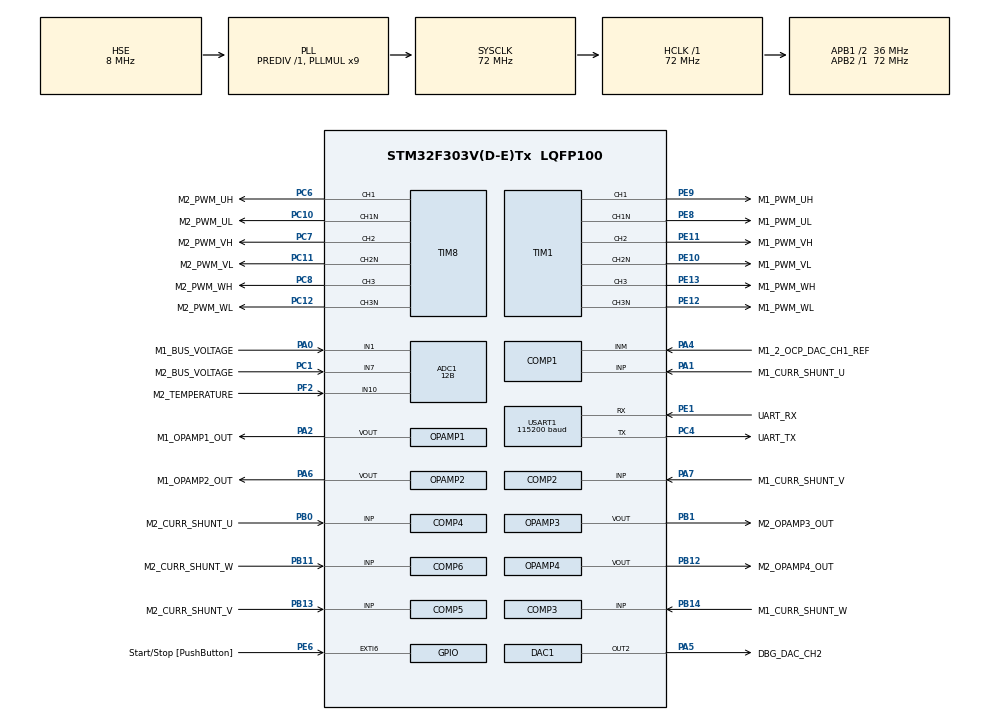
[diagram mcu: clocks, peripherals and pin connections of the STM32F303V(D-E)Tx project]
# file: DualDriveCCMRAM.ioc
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ADC1.Channel-1\#ChannelRegularConversion=ADC_CHANNEL_1
ADC1.Channel-2\#ChannelRegularConversion=ADC_CHANNEL_7
ADC1.Channel-3\#ChannelRegularConversion=ADC_CHANNEL_10
ADC1.ClockPrescaler=ADC_CLOCK_SYNC_PCLK_DIV4
ADC1.ContinuousConvMode=DISABLE
ADC1.DMAContinuousRequests=DISABLE
ADC1.DataAlign=ADC_DATAALIGN_LEFT
ADC1.DiscontinuousConvMode=DISABLE
ADC1.EOCSelection=ADC_EOC_SINGLE_CONV
ADC1.EnableAnalogWatchDog1=false
ADC1.EnableAnalogWatchDog2=false
ADC1.EnableAnalogWatchDog3=false
ADC1.EnableInjectedConversion=ENABLE
ADC1.EnableRegularConversion=ENABLE
ADC1.ExternalTrigConv=ADC_SOFTWARE_START
ADC1.ExternalTrigConvEdge=ADC_EXTERNALTRIGCONVEDGE_NONE
ADC1.ExternalTrigInjecConv=ADC_EXTERNALTRIGINJECCONV_T1_TRGO
ADC1.ExternalTrigInjecConvEdge=ADC_EXTERNALTRIGINJECCONV_EDGE_RISING
ADC1.InjNumberOfConversion=1
ADC1.InjectedChannel-1\#ChannelInjectedConversion=ADC_CHANNEL_3
ADC1.InjectedConvMode=None
ADC1.InjectedOffset-1\#ChannelInjectedConversion=0
ADC1.InjectedOffsetNumber-1\#ChannelInjectedConversion=ADC_OFFSET_NONE
ADC1.InjectedRank-1\#ChannelInjectedConversion=1
ADC1.InjectedSamplingTime-1\#ChannelInjectedConversion=ADC_SAMPLETIME_7CYCLES_5
ADC1.LowPowerAutoWait=DISABLE
ADC1.NbrOfConversion=3
ADC1.NbrOfConversionFlag=1
ADC1.Offset-1\#ChannelRegularConversion=0
ADC1.Offset-2\#ChannelRegularConversion=0
ADC1.Offset-3\#ChannelRegularConversion=0
ADC1.OffsetNumber-1\#ChannelRegularConversion=ADC_OFFSET_NONE
ADC1.OffsetNumber-2\#ChannelRegularConversion=ADC_OFFSET_NONE
ADC1.OffsetNumber-3\#ChannelRegularConversion=ADC_OFFSET_NONE
ADC1.Overrun=ADC_OVR_DATA_PRESERVED
ADC1.QueueInjectedContext=ENABLE
ADC1.Rank-1\#ChannelRegularConversion=1
ADC1.Rank-2\#ChannelRegularConversion=2
ADC1.Rank-3\#ChannelRegularConversion=3
ADC1.Resolution=ADC_RESOLUTION_12B
ADC1.SamplingTime-1\#ChannelRegularConversion=ADC_SAMPLETIME_61CYCLES_5
ADC1.SamplingTime-2\#ChannelRegularConversion=ADC_SAMPLETIME_61CYCLES_5
ADC1.SamplingTime-3\#ChannelRegularConversion=ADC_SAMPLETIME_61CYCLES_5
ADC1.ScanConvMode=ADC_SCAN_ENABLE
ADC1.master=1
ADC2.ClockPrescaler=ADC_CLOCK_SYNC_PCLK_DIV4
ADC2.ContinuousConvMode=DISABLE
ADC2.DMAContinuousRequests=DISABLE
ADC2.DataAlign=ADC_DATAALIGN_LEFT
ADC2.DiscontinuousConvMode=DISABLE
ADC2.EOCSelection=ADC_EOC_SINGLE_CONV
ADC2.EnableAnalogWatchDog1=false
ADC2.EnableAnalogWatchDog2=false
ADC2.EnableAnalogWatchDog3=false
ADC2.EnableInjectedConversion=ENABLE
ADC2.EnableRegularConversion=DISABLE
ADC2.ExternalTrigInjecConv=ADC_EXTERNALTRIGINJECCONV_T1_TRGO
ADC2.ExternalTrigInjecConvEdge=ADC_EXTERNALTRIGINJECCONV_EDGE_RISING
ADC2.InjNumberOfConversion=1
ADC2.InjectedChannel-1\#ChannelInjectedConversion=ADC_CHANNEL_3
ADC2.InjectedConvMode=None
ADC2.InjectedOffset-1\#ChannelInjectedConversion=0
ADC2.InjectedOffsetNumber-1\#ChannelInjectedConversion=ADC_OFFSET_NONE
ADC2.InjectedRank-1\#ChannelInjectedConversion=1
ADC2.InjectedSamplingTime-1\#ChannelInjectedConversion=ADC_SAMPLETIME_7CYCLES_5
ADC2.LowPowerAutoWait=DISABLE
ADC2.Overrun=ADC_OVR_DATA_PRESERVED
ADC2.QueueInjectedContext=ENABLE
ADC2.Resolution=ADC_RESOLUTION_12B
ADC2.ScanConvMode=ADC_SCAN_DISABLE
ADC2.master=1
ADC3.ClockPrescaler=ADC_CLOCK_SYNC_PCLK_DIV4
ADC3.ContinuousConvMode=DISABLE
ADC3.DMAContinuousRequests=DISABLE
ADC3.DataAlign=ADC_DATAALIGN_LEFT
ADC3.DiscontinuousConvMode=DISABLE
ADC3.EOCSelection=ADC_EOC_SINGLE_CONV
ADC3.EnableAnalogWatchDog1=false
ADC3.EnableAnalogWatchDog2=false
ADC3.EnableAnalogWatchDog3=false
ADC3.EnableInjectedConversion=ENABLE
ADC3.EnableRegularConversion=DISABLE
ADC3.ExternalTrigInjecConv=ADC_EXTERNALTRIGINJECCONV_T8_TRGO
ADC3.ExternalTrigInjecConvEdge=ADC_EXTERNALTRIGINJECCONV_EDGE_RISING
ADC3.InjNumberOfConversion=1
ADC3.InjectedChannel-1\#ChannelInjectedConversion=ADC_CHANNEL_1
ADC3.InjectedConvMode=None
ADC3.InjectedOffset-1\#ChannelInjectedConversion=0
ADC3.InjectedOffsetNumber-1\#ChannelInjectedConversion=ADC_OFFSET_NONE
ADC3.InjectedRank-1\#ChannelInjectedConversion=1
ADC3.InjectedSamplingTime-1\#ChannelInjectedConversion=ADC_SAMPLETIME_7CYCLES_5
ADC3.LowPowerAutoWait=DISABLE
ADC3.Overrun=ADC_OVR_DATA_PRESERVED
ADC3.QueueInjectedContext=ENABLE
ADC3.Resolution=ADC_RESOLUTION_12B
ADC3.ScanConvMode=ADC_SCAN_DISABLE
ADC3.master=1
ADC4.ClockPrescaler=ADC_CLOCK_SYNC_PCLK_DIV4
ADC4.ContinuousConvMode=DISABLE
ADC4.DMAContinuousRequests=DISABLE
ADC4.DataAlign=ADC_DATAALIGN_LEFT
ADC4.DiscontinuousConvMode=DISABLE
ADC4.EOCSelection=ADC_EOC_SINGLE_CONV
ADC4.EnableAnalogWatchDog1=false
ADC4.EnableAnalogWatchDog2=false
ADC4.EnableAnalogWatchDog3=false
ADC4.EnableInjectedConversion=ENABLE
ADC4.EnableRegularConversion=DISABLE
ADC4.ExternalTrigInjecConv=ADC_EXTERNALTRIGINJECCONV_T8_TRGO
ADC4.ExternalTrigInjecConvEdge=ADC_EXTERNALTRIGINJECCONV_EDGE_RISING
ADC4.InjNumberOfConversion=1
ADC4.InjectedChannel-1\#ChannelInjectedConversion=ADC_CHANNEL_3
ADC4.InjectedConvMode=None
ADC4.InjectedOffset-1\#ChannelInjectedConversion=0
ADC4.InjectedOffsetNumber-1\#ChannelInjectedConversion=ADC_OFFSET_NONE
ADC4.InjectedRank-1\#ChannelInjectedConversion=1
ADC4.InjectedSamplingTime-1\#ChannelInjectedConversion=ADC_SAMPLETIME_7CYCLES_5
ADC4.LowPowerAutoWait=DISABLE
ADC4.Overrun=ADC_OVR_DATA_PRESERVED
ADC4.QueueInjectedContext=ENABLE
ADC4.Resolution=ADC_RESOLUTION_12B
ADC4.ScanConvMode=ADC_SCAN_DISABLE
ADC4.master=1
COMP1.Output=COMP_OUTPUT_TIM1BKIN2
COMP2.Output=COMP_OUTPUT_TIM1BKIN2
COMP3.Output=COMP_OUTPUT_TIM1BKIN2
COMP4.Output=COMP_OUTPUT_TIM8BKIN2
COMP5.InvertingInput=COMP_INVERTINGINPUT_DAC1_CH1
COMP5.Output=COMP_OUTPUT_TIM8BKIN2
COMP6.InvertingInput=COMP_INVERTINGINPUT_DAC1_CH1
COMP6.Output=COMP_OUTPUT_TIM8BKIN2
DAC1.DAC_OutputBuffer=DAC_OUTPUTBUFFER_DISABLE
DAC1.DAC_OutputBuffer2=DAC_OUTPUTBUFFER_DISABLE
DAC1.DAC_Trigger=DAC_TRIGGER_SOFTWARE
DAC1.DAC_Trigger2=DAC_TRIGGER_SOFTWARE
ExtraMW=MotorControl
ExtraMW.MotorControl.Config=MotorControl
ExtraMW.MotorControl.Mode=MotorControl
ExtraMW.MotorControl.Root=MCSDK_v5.1.2/MotorControl
ExtraMW.MotorControl.Template=templates
Mcu.Family=STM32F3
Mcu.Name=STM32F303V(D-E)Tx
Mcu.Package=LQFP100
MotorControl.ADC_1_PERIPH=ADC1
MotorControl.ADC_1_PERIPH2=ADC3
MotorControl.ADC_2_PERIPH=ADC2
MotorControl.ADC_2_PERIPH2=ADC4
MotorControl.ADC_AHBPERIPH=RCC_AHBPeriph_ADC12
MotorControl.ADC_AHBPERIPH2=RCC_AHBPeriph_ADC34
MotorControl.ADC_CLOCK_WB_DIV=4
MotorControl.ADC_CLOCK_WB_DIV2=4
MotorControl.ADC_CLOCK_WB_FREQ=18
MotorControl.ADC_CLOCK_WB_FREQ2=18
MotorControl.ADC_PERIPH=ADC1
MotorControl.ADC_PERIPH2=ADC3
MotorControl.ALIGNMENT_ANGLE_DEG=90
MotorControl.ALIGNMENT_ANGLE_DEG2=90
MotorControl.ALIGNMENT_DURATION=700
MotorControl.ALIGNMENT_DURATION2=700
MotorControl.AMPLIFICATION_GAIN=1.45
MotorControl.AMPLIFICATION_GAIN2=1.45
MotorControl.ANGC={0,0,0,0,0,0,0,0}
MotorControl.ANGC2={0,0,0,0,0,0,0,0}
MotorControl.BEMF_CONSISTENCY_GAIN=64
MotorControl.BEMF_CONSISTENCY_GAIN2=64
MotorControl.BEMF_CONSISTENCY_TOL=64
MotorControl.BEMF_CONSISTENCY_TOL2=64
MotorControl.BKIN1_FILTER=0
MotorControl.BKIN1_FILTER2=0
MotorControl.BKIN2_FILTER=4
MotorControl.BKIN2_FILTER2=4
MotorControl.BKIN2_MODE=INT_MODE
MotorControl.BKIN2_MODE2=INT_MODE
MotorControl.BKIN_MODE=NONE
MotorControl.BKIN_MODE2=NONE
MotorControl.BOARD=CUSTOM
MotorControl.BRKIN2_GPIO_AF=GPIO_AF_6
MotorControl.BRKIN2_GPIO_AF2=GPIO_AF_10
MotorControl.BRKIN_GPIO_AF=GPIO_AF_2
MotorControl.BRKIN_GPIO_AF2=GPIO_AF_2
MotorControl.BUS_VOLTAGE_READING=true
MotorControl.BUS_VOLTAGE_READING2=true
MotorControl.CCMRAM_ENABLED=true
MotorControl.CLOCK_FREQUENCY=CPU_CLK_72_MHZ
MotorControl.CLOCK_SOURCE=EXTERNAL
MotorControl.CONSTANT1_D=5878
MotorControl.CONSTANT1_D2=5878
MotorControl.CONSTANT1_Q=5878
MotorControl.CONSTANT1_Q2=5878
MotorControl.CONSTANT2_QD=7887
MotorControl.CONSTANT2_QD2=7887
MotorControl.CORD_BEMF_CONSISTENCY_GAIN=64
MotorControl.CORD_BEMF_CONSISTENCY_GAIN2=64
MotorControl.CORD_BEMF_CONSISTENCY_TOL=64
MotorControl.CORD_BEMF_CONSISTENCY_TOL2=64
MotorControl.CORD_F1=2048
MotorControl.CORD_F12=2048
MotorControl.CORD_F2=16384
MotorControl.CORD_F22=16384
MotorControl.CORD_FIFO_DEPTH_01HZ=64
MotorControl.CORD_FIFO_DEPTH_01HZ2=64
MotorControl.CORD_FIFO_DEPTH_DPP=64
MotorControl.CORD_FIFO_DEPTH_DPP2=64
MotorControl.CORD_GAIN1=-3012
MotorControl.CORD_GAIN12=-3012
MotorControl.CORD_GAIN2=15648
MotorControl.CORD_GAIN22=15648
MotorControl.CORD_MAX_ACCEL_DPPP=34
MotorControl.CORD_MAX_ACCEL_DPPP2=34
MotorControl.CORD_MEAS_ERRORS_BEFORE_FAULTS=20
MotorControl.CORD_MEAS_ERRORS_BEFORE_FAULTS2=20
MotorControl.CORD_VARIANCE_THRESHOLD=4
MotorControl.CORD_VARIANCE_THRESHOLD2=4
MotorControl.CPU_CLK_72_MHZ=true
MotorControl.CTRBDID=3
MotorControl.CTRBDID2=3
MotorControl.CURRENT_READING_TOPOLOGY=THREE_SHUNT_INDEPENDENT_RESOURCES
MotorControl.CURRENT_READING_TOPOLOGY2=THREE_SHUNT_INDEPENDENT_RESOURCES2
MotorControl.CURR_SAMPLING_TIME=7
MotorControl.CURR_SAMPLING_TIME2=7
MotorControl.DAC_EMULATED=false
MotorControl.DAC_FUNCTIONALITY=true
MotorControl.DAC_FUNCTIONALITY2=true
MotorControl.DAC_TIMER_CH1_GPIO_PIN=LL_GPIO_PIN_4
MotorControl.DAC_TIMER_CH1_GPIO_PIN2=LL_GPIO_PIN_4
MotorControl.DAC_TIMER_CH1_GPIO_PORT=GPIOA
MotorControl.DAC_TIMER_CH1_GPIO_PORT2=GPIOA
MotorControl.DAC_TIMER_CH2_GPIO_PIN=LL_GPIO_PIN_5
MotorControl.DAC_TIMER_CH2_GPIO_PIN2=LL_GPIO_PIN_5
MotorControl.DAC_TIMER_CH2_GPIO_PORT=GPIOA
MotorControl.DAC_TIMER_CH2_GPIO_PORT2=GPIOA
MotorControl.DAC_TIMER_REMAPPING=NO_REMAP
MotorControl.DAC_TIMER_REMAPPING2=NO_REMAP
MotorControl.DAC_TIMER_SELECTION=TIM3
MotorControl.DAC_TIMER_SELECTION2=TIM3
MotorControl.DC_CURRENT_RS_MEAS=1.60
MotorControl.DC_CURRENT_RS_MEAS2=1.60
MotorControl.DEBUG_DAC_CH1=false
MotorControl.DEBUG_DAC_CH12=false
MotorControl.DEBUG_DAC_CH2=true
MotorControl.DEBUG_DAC_CH22=true
MotorControl.DEFAULT_CONTROL_MODE=STC_SPEED_MODE
MotorControl.DEFAULT_CONTROL_MODE2=STC_SPEED_MODE
MotorControl.DEFAULT_DAC_CHANNEL_1=MC_PROTOCOL_REG_I_A
MotorControl.DEFAULT_DAC_CHANNEL_12=MC_PROTOCOL_REG_I_A
MotorControl.DEFAULT_DAC_CHANNEL_2=MC_PROTOCOL_REG_I_B
MotorControl.DEFAULT_DAC_CHANNEL_22=MC_PROTOCOL_REG_I_B
MotorControl.DEFAULT_DAC_MOTOR=2
MotorControl.DEFAULT_DAC_MOTOR2=2
MotorControl.DEFAULT_FLUX_COMPONENT=0
MotorControl.DEFAULT_FLUX_COMPONENT2=0
MotorControl.DEFAULT_TARGET_SPEED_RPM=1440
MotorControl.DEFAULT_TARGET_SPEED_RPM2=1440
MotorControl.DEFAULT_TORQUE_COMPONENT=0
MotorControl.DEFAULT_TORQUE_COMPONENT2=0
MotorControl.DISSIPATIVE_BRAKE_POLARITY=DOUT_ACTIVE_HIGH
MotorControl.DISSIPATIVE_BRAKE_POLARITY2=DOUT_ACTIVE_HIGH
MotorControl.DRIVES_NUMBER_SELECTION=DUALDRIVE
MotorControl.DUALDRIVE=true
MotorControl.EMERGENCY2_STOP_GPIO_PIN=LL_GPIO_PIN_14
MotorControl.EMERGENCY2_STOP_GPIO_PIN2=LL_GPIO_PIN_6
MotorControl.EMERGENCY2_STOP_GPIO_PORT=GPIOE
MotorControl.EMERGENCY2_STOP_GPIO_PORT2=GPIOB
MotorControl.EMERGENCY_STOP_GPIO_PIN=LL_GPIO_PIN_14
MotorControl.EMERGENCY_STOP_GPIO_PIN2=LL_GPIO_PIN_6
MotorControl.EMERGENCY_STOP_GPIO_PORT=GPIOE
MotorControl.EMERGENCY_STOP_GPIO_PORT2=GPIOB
MotorControl.ENABLE_SL_ALGO_FROM_PHASE=2
MotorControl.ENABLE_SL_ALGO_FROM_PHASE2=2
MotorControl.ENCODER_AVAILABLE=true
MotorControl.ENCODER_AVAILABLE2=true
MotorControl.ENCODER_PPR=400
MotorControl.ENCODER_PPR2=400
MotorControl.ENC_AVERAGING_FIFO_DEPTH=16
MotorControl.ENC_AVERAGING_FIFO_DEPTH2=16
MotorControl.ENC_A_GPIO_PIN=LL_GPIO_PIN_3
MotorControl.ENC_A_GPIO_PIN2=LL_GPIO_PIN_6
MotorControl.ENC_A_GPIO_PORT=GPIOD
MotorControl.ENC_A_GPIO_PORT2=GPIOB
MotorControl.ENC_B_GPIO_PIN=LL_GPIO_PIN_4
MotorControl.ENC_B_GPIO_PIN2=LL_GPIO_PIN_13
MotorControl.ENC_B_GPIO_PORT=GPIOD
MotorControl.ENC_B_GPIO_PORT2=GPIOD
MotorControl.ENC_ICx_FILTER=50
MotorControl.ENC_ICx_FILTER2=50
MotorControl.ENC_INVERT_SPEED=false
MotorControl.ENC_INVERT_SPEED2=false
MotorControl.ENC_MEAS_ERRORS_BEFORE_FAULTS=20
MotorControl.ENC_MEAS_ERRORS_BEFORE_FAULTS2=20
MotorControl.ENC_TIMER_REMAPPING=NO_REMAP_TIM2
MotorControl.ENC_TIMER_REMAPPING2=NO_REMAP_TIM4
MotorControl.ENC_TIMER_SELECTION=ENC_TIM2
MotorControl.ENC_TIMER_SELECTION2=ENC_TIM4
MotorControl.EXT_CLK_8_MHZ=true
MotorControl.EXT_CLOCK_FREQUENCY=EXT_CLK_8_MHZ
MotorControl.F1=2048
MotorControl.F12=2048
MotorControl.F2=16384
MotorControl.F22=16384
MotorControl.FEEDBACK_NET_FILTERING=false
MotorControl.FEEDBACK_NET_FILTERING2=false
MotorControl.FEED_FORWARD_CURRENT_REG_ENABLING=false
MotorControl.FEED_FORWARD_CURRENT_REG_ENABLING2=false
MotorControl.FINAL_I_ALIGNMENT=26390
MotorControl.FINAL_I_ALIGNMENT2=26390
MotorControl.FLUX_WEAKENING_ENABLING=false
MotorControl.FLUX_WEAKENING_ENABLING2=false
MotorControl.FREQ_RATIO2=1
MotorControl.FREQ_RELATION2=HIGHEST_FREQ
MotorControl.FREQ_RELATION22=LOWEST_FREQ
MotorControl.FW_KIDIV=32768
MotorControl.FW_KIDIV2=32768
MotorControl.FW_KI_GAIN=5000
MotorControl.FW_KI_GAIN2=5000
MotorControl.FW_KPDIV=32768
MotorControl.FW_KPDIV2=32768
MotorControl.FW_KP_GAIN=3000
MotorControl.FW_KP_GAIN2=3000
MotorControl.FW_VOLTAGE_REF=985
MotorControl.FW_VOLTAGE_REF2=985
MotorControl.GAIN1=-3012
MotorControl.GAIN12=-3012
MotorControl.GAIN2=15648
MotorControl.GAIN22=15648
MotorControl.H1_GPIO_PIN=LL_GPIO_PIN_3
MotorControl.H1_GPIO_PIN2=LL_GPIO_PIN_6
MotorControl.H1_GPIO_PORT=GPIOD
MotorControl.H1_GPIO_PORT2=GPIOB
MotorControl.H2_GPIO_PIN=LL_GPIO_PIN_4
MotorControl.H2_GPIO_PIN2=LL_GPIO_PIN_13
MotorControl.H2_GPIO_PORT=GPIOD
MotorControl.H2_GPIO_PORT2=GPIOD
MotorControl.H3_GPIO_PIN=LL_GPIO_PIN_7
MotorControl.H3_GPIO_PIN2=LL_GPIO_PIN_8
MotorControl.H3_GPIO_PORT=GPIOD
MotorControl.H3_GPIO_PORT2=GPIOB
MotorControl.HALL_AVERAGING_FIFO_DEPTH=6
MotorControl.HALL_AVERAGING_FIFO_DEPTH2=6
MotorControl.HALL_ICx_FILTER=94
MotorControl.HALL_ICx_FILTER2=94
MotorControl.HALL_MEAS_ERRORS_BEFORE_FAULTS=20
MotorControl.HALL_MEAS_ERRORS_BEFORE_FAULTS2=20
MotorControl.HALL_PHASE_SHIFT=300
MotorControl.HALL_PHASE_SHIFT2=300
MotorControl.HALL_SENSORS_AVAILABLE=true
MotorControl.HALL_SENSORS_AVAILABLE2=true
MotorControl.HALL_SENSORS_PLACEMENT=DEGREES_120
MotorControl.HALL_SENSORS_PLACEMENT2=DEGREES_120
MotorControl.HALL_TIMER_REMAPPING=NO_REMAP_TIM2
MotorControl.HALL_TIMER_REMAPPING2=NO_REMAP_TIM4
MotorControl.HALL_TIMER_SELECTION=HALL_TIM2
MotorControl.HALL_TIMER_SELECTION2=HALL_TIM4
MotorControl.HFI_AMPLITUDE=25
MotorControl.HFI_AMPLITUDE2=25
MotorControl.HFI_DC_0_COEFF=0.00146
MotorControl.HFI_DC_0_COEFF2=0.00146
MotorControl.HFI_DC_1_COEFF=0.002921
MotorControl.HFI_DC_1_COEFF2=0.002921
MotorControl.HFI_DC_2_COEFF=0.00146
MotorControl.HFI_DC_2_COEFF2=0.00146
MotorControl.HFI_DC_3_COEFF=1.889033
MotorControl.HFI_DC_3_COEFF2=1.889033
MotorControl.HFI_DC_4_COEFF=-0.894874
MotorControl.HFI_DC_4_COEFF2=-0.894874
MotorControl.HFI_DEBUG_MODE=false
MotorControl.HFI_DEBUG_MODE2=false
MotorControl.HFI_FREQUENCY=400
MotorControl.HFI_FREQUENCY2=400
MotorControl.HFI_HIFRAMPLSCAN=25
MotorControl.HFI_HIFRAMPLSCAN2=25
MotorControl.HFI_HP_ID_0_COEFF=0.920407
MotorControl.HFI_HP_ID_0_COEFF2=0.920407
MotorControl.HFI_HP_ID_1_COEFF=-1.840814
MotorControl.HFI_HP_ID_1_COEFF2=-1.840814
MotorControl.HFI_HP_ID_2_COEFF=0.920407
MotorControl.HFI_HP_ID_2_COEFF2=0.920407
MotorControl.HFI_HP_ID_3_COEFF=1.834469
MotorControl.HFI_HP_ID_3_COEFF2=1.834469
MotorControl.HFI_HP_ID_4_COEFF=-0.847159
MotorControl.HFI_HP_ID_4_COEFF2=-0.847159
MotorControl.HFI_IDH_DELAY=32400
MotorControl.HFI_IDH_DELAY2=32400
MotorControl.HFI_LOCKFREQ=44
MotorControl.HFI_LOCKFREQ2=44
MotorControl.HFI_LP_ID_0_COEFF=0.010248
MotorControl.HFI_LP_ID_0_COEFF2=0.010248
MotorControl.HFI_LP_ID_1_COEFF=0.020497
MotorControl.HFI_LP_ID_1_COEFF2=0.020497
MotorControl.HFI_LP_ID_2_COEFF=0.010248
MotorControl.HFI_LP_ID_2_COEFF2=0.010248
MotorControl.HFI_LP_ID_3_COEFF=1.693906
MotorControl.HFI_LP_ID_3_COEFF2=1.693906
MotorControl.HFI_LP_ID_4_COEFF=-0.734899
MotorControl.HFI_LP_ID_4_COEFF2=-0.734899
MotorControl.HFI_MAXANGLEDIFF=3640
MotorControl.HFI_MAXANGLEDIFF2=3640
MotorControl.HFI_MINIMUM_SPEED_RPM=402
MotorControl.HFI_MINIMUM_SPEED_RPM2=402
MotorControl.HFI_NOTCH_IQD_0_COEFF=0.959976
MotorControl.HFI_NOTCH_IQD_0_COEFF2=0.959976
MotorControl.HFI_NOTCH_IQD_1_COEFF=-1.893066
MotorControl.HFI_NOTCH_IQD_1_COEFF2=-1.893066
MotorControl.HFI_NOTCH_IQD_2_COEFF=0.959976
MotorControl.HFI_NOTCH_IQD_2_COEFF2=0.959976
MotorControl.HFI_NOTCH_IQD_3_COEFF=1.893066
MotorControl.HFI_NOTCH_IQD_3_COEFF2=1.893066
MotorControl.HFI_NOTCH_IQD_4_COEFF=-0.919953
MotorControl.HFI_NOTCH_IQD_4_COEFF2=-0.919953
MotorControl.HFI_NSDETPOINTSSKIP=10
MotorControl.HFI_NSDETPOINTSSKIP2=10
MotorControl.HFI_NSMAXDETPOINTS=20
MotorControl.HFI_NSMAXDETPOINTS2=20
MotorControl.HFI_NS_MIN_SAT_DIFF=0
MotorControl.HFI_NS_MIN_SAT_DIFF2=0
MotorControl.HFI_PID_KIDIV=32768
MotorControl.HFI_PID_KIDIV2=32768
MotorControl.HFI_PID_KI_DEFAULT=400
MotorControl.HFI_PID_KI_DEFAULT2=400
MotorControl.HFI_PID_KPDIV=16384
MotorControl.HFI_PID_KPDIV2=16384
MotorControl.HFI_PID_KP_DEFAULT=800
MotorControl.HFI_PID_KP_DEFAULT2=800
MotorControl.HFI_PLL_KI_DEFAULT=0.00400
MotorControl.HFI_PLL_KI_DEFAULT2=0.00400
MotorControl.HFI_PLL_KP_DEFAULT=0.00060
MotorControl.HFI_PLL_KP_DEFAULT2=0.00060
MotorControl.HFI_RESTARTTIMESEC=0.1
MotorControl.HFI_RESTARTTIMESEC2=0.1
MotorControl.HFI_RESTART_RPM_TH=(((HFI_STO_RPM_TH)+(STO_HFI_RPM_TH))/2)
MotorControl.HFI_RESTART_RPM_TH2=(((HFI_STO_RPM_TH2)+(STO_HFI_RPM_TH2))/2)
MotorControl.HFI_REVERT_DIRECTION=true
MotorControl.HFI_REVERT_DIRECTION2=true
MotorControl.HFI_SCANROTATIONSNO=3
MotorControl.HFI_SCANROTATIONSNO2=3
MotorControl.HFI_SPD_BUFFER_DEPTH_01HZ=64
MotorControl.HFI_SPD_BUFFER_DEPTH_01HZ2=64
MotorControl.HFI_STEPANGLE=3640
MotorControl.HFI_STEPANGLE2=3640
MotorControl.HFI_STO_RPM_TH=OBS_MINIMUM_SPEED_RPM
MotorControl.HFI_STO_RPM_TH2=OBS_MINIMUM_SPEED_RPM2
MotorControl.HFI_WAITAFTERNS2=4
MotorControl.HFI_WAITAFTERNS22=4
MotorControl.HFI_WAITBEFORESN=6
MotorControl.HFI_WAITBEFORESN2=6
MotorControl.HFI_WAITSYNCH=20
MotorControl.HFI_WAITSYNCH2=20
MotorControl.HFI_WAITTRACK=20
MotorControl.HFI_WAITTRACK2=20
MotorControl.HIGH_SIDE_BRAKE_STATE=false
MotorControl.HIGH_SIDE_BRAKE_STATE2=false
MotorControl.HIGH_SIDE_IDLE_STATE=false
MotorControl.HIGH_SIDE_IDLE_STATE2=false
MotorControl.HW_COMPLEMENTED_LOW_SIDE=false
MotorControl.HW_COMPLEMENTED_LOW_SIDE2=false
MotorControl.HW_DEAD_TIME_NS=100
MotorControl.HW_DEAD_TIME_NS2=100
MotorControl.HW_OV_CURRENT_PROT_BYPASS=false
MotorControl.HW_OV_CURRENT_PROT_BYPASS2=false
MotorControl.ID_DEMAG=-21654
MotorControl.ID_DEMAG2=-21654
MotorControl.INRUSH_CURRLIMIT_AT_POWER_ON=true
MotorControl.INRUSH_CURRLIMIT_AT_POWER_ON2=false
MotorControl.INRUSH_CURRLIMIT_CHANGE_AFTER_MS=1000
MotorControl.INRUSH_CURRLIMIT_CHANGE_AFTER_MS2=1000
MotorControl.INRUSH_CURRLIMIT_ENABLING=false
MotorControl.INRUSH_CURRLIMIT_ENABLING2=false
MotorControl.INRUSH_CURRLIMIT_GPIO_PIN=LL_GPIO_PIN_4
MotorControl.INRUSH_CURRLIMIT_GPIO_PIN2=LL_GPIO_PIN_15
MotorControl.INRUSH_CURRLIMIT_GPIO_PORT=GPIOE
MotorControl.INRUSH_CURRLIMIT_GPIO_PORT2=GPIOD
MotorControl.INRUSH_CURR_LIMITER_POLARITY=DOUT_ACTIVE_HIGH
MotorControl.INRUSH_CURR_LIMITER_POLARITY2=DOUT_ACTIVE_HIGH
MotorControl.INTERNAL_OVERCURRENTPROTECTION=true
MotorControl.INTERNAL_OVERCURRENTPROTECTION2=true
MotorControl.INTERNAL_OVERVOLTAGEPROTECTION=false
MotorControl.INTERNAL_OVERVOLTAGEPROTECTION2=false
MotorControl.IQMAX=21654
MotorControl.IQMAX2=21654
MotorControl.LCD_JOYSTICK_FUNCTIONALITY=false
MotorControl.LCD_JOYSTICK_FUNCTIONALITY2=false
MotorControl.LCD_MODE=LCD_FULL
MotorControl.LCD_MODE2=LCD_FULL
MotorControl.LDLQ_RATIO=1.000
MotorControl.LDLQ_RATIO2=1.000
MotorControl.LOW_SIDE_BRAKE_STATE=false
MotorControl.LOW_SIDE_BRAKE_STATE2=false
MotorControl.LOW_SIDE_IDLE_STATE=false
MotorControl.LOW_SIDE_IDLE_STATE2=false
MotorControl.LOW_SIDE_SIGNALS_ENABLING=LS_PWM_TIMER
MotorControl.LOW_SIDE_SIGNALS_ENABLING2=LS_PWM_TIMER
MotorControl.LS=0.000600
MotorControl.LS2=0.000600
MotorControl.MAX_APPLICATION_SPEED=4000
MotorControl.MAX_APPLICATION_SPEED2=4000
MotorControl.MAX_MODULATION_INDEX=MAX_MODULATION_93_PER_CENT
MotorControl.MAX_MODULATION_INDEX2=MAX_MODULATION_93_PER_CENT2
MotorControl.MCU=STM32F303VE
MotorControl.MCU_SUPPLY_VOLTAGE=3.30
MotorControl.MCU_TYPE=STM32F303xC
MotorControl.MC_WORKBENCH_VERSION=5.1.2.18276
MotorControl.MEAS_ERRORS_BEFORE_FAULTS=20
MotorControl.MEAS_ERRORS_BEFORE_FAULTS2=20
MotorControl.MIN_APPLICATION_SPEED=0
MotorControl.MIN_APPLICATION_SPEED2=0
MotorControl.MOTOR_MAX_SPEED_RPM=4000
MotorControl.MOTOR_MAX_SPEED_RPM2=4000
MotorControl.MOTOR_TYPE=PMSM
MotorControl.MOTOR_TYPE2=PMSM
MotorControl.MOTOR_VOLTAGE_CONSTANT=4.0
MotorControl.MOTOR_VOLTAGE_CONSTANT2=4.0
MotorControl.MTPA_ENABLING=false
MotorControl.MTPA_ENABLING2=false
MotorControl.NB_CONSECUTIVE_TESTS=2
MotorControl.NB_CONSECUTIVE_TESTS2=2
MotorControl.NOMINAL_BUS_VOLTAGE_V=24
MotorControl.NOMINAL_BUS_VOLTAGE_V2=24
MotorControl.NOMINAL_CURRENT=21654
MotorControl.NOMINAL_CURRENT2=21654
MotorControl.OBS_MEAS_ERRORS_BEFORE_FAULTS=20
MotorControl.OBS_MEAS_ERRORS_BEFORE_FAULTS2=20
MotorControl.OBS_MINIMUM_SPEED_RPM=1440
MotorControl.OBS_MINIMUM_SPEED_RPM2=1440
MotorControl.OCPA_INVERTINGINPUT=COMPX_InvertingInput_DAC1
MotorControl.OCPA_INVERTINGINPUT2=COMPX_InvertingInput_DAC1
MotorControl.OCPA_INVERTINGINPUT_GPIO_PIN=LL_GPIO_PIN_4
MotorControl.OCPA_INVERTINGINPUT_GPIO_PIN2=LL_GPIO_PIN_4
MotorControl.OCPA_INVERTINGINPUT_GPIO_PORT=GPIOA
MotorControl.OCPA_INVERTINGINPUT_GPIO_PORT2=GPIOA
MotorControl.OCPA_INVERTINGINPUT_MODE=INT_MODE
MotorControl.OCPA_INVERTINGINPUT_MODE2=INT_MODE
MotorControl.OCPA_NONINVERTINGINPUT=COMP1_NonInvertingInput_PA1
MotorControl.OCPA_NONINVERTINGINPUT2=COMP4_NonInvertingInput_PB0
MotorControl.OCPA_NONINVERTINGINPUT_GPIO_PIN=LL_GPIO_PIN_1
MotorControl.OCPA_NONINVERTINGINPUT_GPIO_PIN2=LL_GPIO_PIN_0
MotorControl.OCPA_NONINVERTINGINPUT_GPIO_PORT=GPIOA
MotorControl.OCPA_NONINVERTINGINPUT_GPIO_PORT2=GPIOB
MotorControl.OCPA_OUTPUT=COMP_Output_TIM1BKIN2
MotorControl.OCPA_OUTPUT2=COMP_Output_TIM8BKIN2
MotorControl.OCPA_OUTPUTPOL=COMP_OutputPol_NonInverted
MotorControl.OCPA_OUTPUTPOL2=COMP_OutputPol_NonInverted
MotorControl.OCPA_OUTPUT_GPIO_AF=GPIO_AF_8
MotorControl.OCPA_OUTPUT_GPIO_AF2=GPIO_AF_8
MotorControl.OCPA_OUTPUT_GPIO_PIN=LL_GPIO_PIN_0
MotorControl.OCPA_OUTPUT_GPIO_PIN2=LL_GPIO_PIN_1
MotorControl.OCPA_OUTPUT_GPIO_PORT=GPIOA
MotorControl.OCPA_OUTPUT_GPIO_PORT2=GPIOB
MotorControl.OCPA_OUTPUT_MODE=INT_MODE
MotorControl.OCPA_OUTPUT_MODE2=INT_MODE
MotorControl.OCPA_SELECTION=COMP1
MotorControl.OCPA_SELECTION2=COMP4
MotorControl.OCPB_INVERTINGINPUT=COMPX_InvertingInput_DAC1
MotorControl.OCPB_INVERTINGINPUT2=COMPX_InvertingInput_DAC1
MotorControl.OCPB_INVERTINGINPUT_GPIO_PIN=LL_GPIO_PIN_4
MotorControl.OCPB_INVERTINGINPUT_GPIO_PIN2=LL_GPIO_PIN_4
MotorControl.OCPB_INVERTINGINPUT_GPIO_PORT=GPIOA
MotorControl.OCPB_INVERTINGINPUT_GPIO_PORT2=GPIOA
MotorControl.OCPB_INVERTINGINPUT_MODE=INT_MODE
MotorControl.OCPB_INVERTINGINPUT_MODE2=INT_MODE
MotorControl.OCPB_NONINVERTINGINPUT=COMP2_NonInvertingInput_PA7
MotorControl.OCPB_NONINVERTINGINPUT2=COMP5_NonInvertingInput_PB13
MotorControl.OCPB_NONINVERTINGINPUT_GPIO_PIN=LL_GPIO_PIN_7
MotorControl.OCPB_NONINVERTINGINPUT_GPIO_PIN2=LL_GPIO_PIN_13
MotorControl.OCPB_NONINVERTINGINPUT_GPIO_PORT=GPIOA
MotorControl.OCPB_NONINVERTINGINPUT_GPIO_PORT2=GPIOB
MotorControl.OCPB_OUTPUT=COMP_Output_TIM1BKIN2
MotorControl.OCPB_OUTPUT2=COMP_Output_TIM8BKIN2
MotorControl.OCPB_OUTPUTPOL=COMP_OutputPol_NonInverted
MotorControl.OCPB_OUTPUTPOL2=COMP_OutputPol_NonInverted
MotorControl.OCPB_OUTPUT_GPIO_AF=GPIO_AF_8
MotorControl.OCPB_OUTPUT_GPIO_AF2=GPIO_AF_7
MotorControl.OCPB_OUTPUT_GPIO_PIN=LL_GPIO_PIN_2
MotorControl.OCPB_OUTPUT_GPIO_PIN2=LL_GPIO_PIN_7
MotorControl.OCPB_OUTPUT_GPIO_PORT=GPIOA
MotorControl.OCPB_OUTPUT_GPIO_PORT2=GPIOC
MotorControl.OCPB_OUTPUT_MODE=INT_MODE
MotorControl.OCPB_OUTPUT_MODE2=INT_MODE
MotorControl.OCPB_SELECTION=COMP2
MotorControl.OCPB_SELECTION2=COMP5
MotorControl.OCPC_INVERTINGINPUT=COMPX_InvertingInput_DAC1
MotorControl.OCPC_INVERTINGINPUT2=COMPX_InvertingInput_DAC1
MotorControl.OCPC_INVERTINGINPUT_GPIO_PIN=LL_GPIO_PIN_4
MotorControl.OCPC_INVERTINGINPUT_GPIO_PIN2=LL_GPIO_PIN_4
MotorControl.OCPC_INVERTINGINPUT_GPIO_PORT=GPIOA
MotorControl.OCPC_INVERTINGINPUT_GPIO_PORT2=GPIOA
MotorControl.OCPC_INVERTINGINPUT_MODE=INT_MODE
MotorControl.OCPC_INVERTINGINPUT_MODE2=INT_MODE
MotorControl.OCPC_NONINVERTINGINPUT=COMP3_NonInvertingInput_PB14
MotorControl.OCPC_NONINVERTINGINPUT2=COMP6_NonInvertingInput_PB11
MotorControl.OCPC_NONINVERTINGINPUT_GPIO_PIN=LL_GPIO_PIN_14
MotorControl.OCPC_NONINVERTINGINPUT_GPIO_PIN2=LL_GPIO_PIN_11
MotorControl.OCPC_NONINVERTINGINPUT_GPIO_PORT=GPIOB
MotorControl.OCPC_NONINVERTINGINPUT_GPIO_PORT2=GPIOB
MotorControl.OCPC_OUTPUT=COMP_Output_TIM1BKIN2
MotorControl.OCPC_OUTPUT2=COMP_Output_TIM8BKIN2
MotorControl.OCPC_OUTPUTPOL=COMP_OutputPol_NonInverted
MotorControl.OCPC_OUTPUTPOL2=COMP_OutputPol_NonInverted
MotorControl.OCPC_OUTPUT_GPIO_AF=GPIO_AF_7
MotorControl.OCPC_OUTPUT_GPIO_AF2=GPIO_AF_8
MotorControl.OCPC_OUTPUT_GPIO_PIN=LL_GPIO_PIN_8
MotorControl.OCPC_OUTPUT_GPIO_PIN2=LL_GPIO_PIN_10
MotorControl.OCPC_OUTPUT_GPIO_PORT=GPIOC
MotorControl.OCPC_OUTPUT_GPIO_PORT2=GPIOA
MotorControl.OCPC_OUTPUT_MODE=INT_MODE
MotorControl.OCPC_OUTPUT_MODE2=INT_MODE
MotorControl.OCPC_SELECTION=COMP3
MotorControl.OCPC_SELECTION2=COMP6
MotorControl.OCPREF=38328
MotorControl.OCPREF2=38328
MotorControl.OCP_COMP_THRESHOLD=0.50
MotorControl.OCP_COMP_THRESHOLD2=0.50
MotorControl.OCP_FILTER=COMP_Mode_HighSpeed
MotorControl.OCP_FILTER2=COMP_Mode_HighSpeed
MotorControl.OCP_INVERTINGINPUT=COMPX_InvertingInput_DAC1
MotorControl.OCP_INVERTINGINPUT2=COMPX_InvertingInput_DAC1
MotorControl.OCP_INVERTINGINPUT_GPIO_PIN=LL_GPIO_PIN_4
MotorControl.OCP_INVERTINGINPUT_GPIO_PIN2=LL_GPIO_PIN_4
MotorControl.OCP_INVERTINGINPUT_GPIO_PORT=GPIOA
MotorControl.OCP_INVERTINGINPUT_GPIO_PORT2=GPIOA
MotorControl.OCP_INVERTINGINPUT_MODE=INT_MODE
MotorControl.OCP_INVERTINGINPUT_MODE2=INT_MODE
MotorControl.OCP_NONINVERTINGINPUT=COMP2_NonInvertingInput_PA7
MotorControl.OCP_NONINVERTINGINPUT2=COMP5_NonInvertingInput_PB13
MotorControl.OCP_NONINVERTINGINPUT_GPIO_PIN=LL_GPIO_PIN_7
MotorControl.OCP_NONINVERTINGINPUT_GPIO_PIN2=LL_GPIO_PIN_13
MotorControl.OCP_NONINVERTINGINPUT_GPIO_PORT=GPIOA
MotorControl.OCP_NONINVERTINGINPUT_GPIO_PORT2=GPIOB
MotorControl.OCP_OUTPUT=COMP_Output_TIM1BKIN2
MotorControl.OCP_OUTPUT2=COMP_Output_TIM8BKIN2
MotorControl.OCP_OUTPUTPOL=COMP_OutputPol_NonInverted
MotorControl.OCP_OUTPUTPOL2=COMP_OutputPol_NonInverted
MotorControl.OCP_OUTPUT_GPIO_AF=GPIO_AF_8
MotorControl.OCP_OUTPUT_GPIO_AF2=GPIO_AF_7
MotorControl.OCP_OUTPUT_GPIO_PIN=LL_GPIO_PIN_2
MotorControl.OCP_OUTPUT_GPIO_PIN2=LL_GPIO_PIN_7
MotorControl.OCP_OUTPUT_GPIO_PORT=GPIOA
MotorControl.OCP_OUTPUT_GPIO_PORT2=GPIOC
MotorControl.OCP_OUTPUT_MODE=INT_MODE
MotorControl.OCP_OUTPUT_MODE2=INT_MODE
MotorControl.OCP_SELECTION=COMP2
MotorControl.OCP_SELECTION2=COMP5
MotorControl.OFST={0,0,0,0,0,0,0,0}
MotorControl.OFST2={0,0,0,0,0,0,0,0}
MotorControl.ON_OVER_VOLTAGE=TURN_OFF_PWM
MotorControl.ON_OVER_VOLTAGE2=TURN_OFF_PWM
MotorControl.OPAMP1_INVERTINGINPUT=OPAMP1_InvertingInput_PGA
MotorControl.OPAMP1_INVERTINGINPUT2=OPAMP3_InvertingInput_PGA
MotorControl.OPAMP1_INVERTINGINPUT_GPIO_PIN=LL_GPIO_PIN_3
MotorControl.OPAMP1_INVERTINGINPUT_GPIO_PIN2=LL_GPIO_PIN_2
MotorControl.OPAMP1_INVERTINGINPUT_GPIO_PORT=GPIOA
MotorControl.OPAMP1_INVERTINGINPUT_GPIO_PORT2=GPIOB
MotorControl.OPAMP1_INVERTINGINPUT_MODE=INT_MODE
MotorControl.OPAMP1_INVERTINGINPUT_MODE2=INT_MODE
MotorControl.OPAMP1_NONINVERTINGINPUT_PHA=OPAMP1_NonInvertingInput_PA1
MotorControl.OPAMP1_NONINVERTINGINPUT_PHA2=OPAMP3_NonInvertingInput_PB0
MotorControl.OPAMP1_NONINVERTINGINPUT_PHA_GPIO_PIN=LL_GPIO_PIN_1
MotorControl.OPAMP1_NONINVERTINGINPUT_PHA_GPIO_PIN2=LL_GPIO_PIN_0
MotorControl.OPAMP1_NONINVERTINGINPUT_PHA_GPIO_PORT=GPIOA
MotorControl.OPAMP1_NONINVERTINGINPUT_PHA_GPIO_PORT2=GPIOB
MotorControl.OPAMP1_NONINVERTINGINPUT_PHB=OPAMP1_NonInvertingInput_PA7
MotorControl.OPAMP1_NONINVERTINGINPUT_PHB2=OPAMP3_NonInvertingInput_PB13
MotorControl.OPAMP1_NONINVERTINGINPUT_PHB_GPIO_PIN=LL_GPIO_PIN_7
MotorControl.OPAMP1_NONINVERTINGINPUT_PHB_GPIO_PIN2=LL_GPIO_PIN_13
MotorControl.OPAMP1_NONINVERTINGINPUT_PHB_GPIO_PORT=GPIOA
MotorControl.OPAMP1_NONINVERTINGINPUT_PHB_GPIO_PORT2=GPIOB
MotorControl.OPAMP1_OUT_GPIO_PIN=LL_GPIO_PIN_2
MotorControl.OPAMP1_OUT_GPIO_PIN2=LL_GPIO_PIN_1
MotorControl.OPAMP1_OUT_GPIO_PORT=GPIOA
MotorControl.OPAMP1_OUT_GPIO_PORT2=GPIOB
MotorControl.OPAMP1_SELECTION=OPAMP1
MotorControl.OPAMP1_SELECTION2=OPAMP3
MotorControl.OPAMP2_INVERTINGINPUT=OPAMP2_InvertingInput_PGA
MotorControl.OPAMP2_INVERTINGINPUT2=OPAMP4_InvertingInput_PGA
MotorControl.OPAMP2_INVERTINGINPUT_GPIO_PIN=LL_GPIO_PIN_5
MotorControl.OPAMP2_INVERTINGINPUT_GPIO_PIN2=LL_GPIO_PIN_10
MotorControl.OPAMP2_INVERTINGINPUT_GPIO_PORT=GPIOC
MotorControl.OPAMP2_INVERTINGINPUT_GPIO_PORT2=GPIOB
MotorControl.OPAMP2_INVERTINGINPUT_MODE=INT_MODE
MotorControl.OPAMP2_INVERTINGINPUT_MODE2=INT_MODE
MotorControl.OPAMP2_NONINVERTINGINPUT_PHA=OPAMP1_NonInvertingInput_PA1
MotorControl.OPAMP2_NONINVERTINGINPUT_PHA2=OPAMP1_NonInvertingInput_PA1
MotorControl.OPAMP2_NONINVERTINGINPUT_PHA_GPIO_PIN=LL_GPIO_PIN_1
MotorControl.OPAMP2_NONINVERTINGINPUT_PHA_GPIO_PIN2=LL_GPIO_PIN_1
MotorControl.OPAMP2_NONINVERTINGINPUT_PHA_GPIO_PORT=GPIOA
MotorControl.OPAMP2_NONINVERTINGINPUT_PHA_GPIO_PORT2=GPIOA
MotorControl.OPAMP2_NONINVERTINGINPUT_PHB=OPAMP2_NonInvertingInput_PA7
MotorControl.OPAMP2_NONINVERTINGINPUT_PHB2=OPAMP4_NonInvertingInput_PB13
MotorControl.OPAMP2_NONINVERTINGINPUT_PHB_GPIO_PIN=LL_GPIO_PIN_7
MotorControl.OPAMP2_NONINVERTINGINPUT_PHB_GPIO_PIN2=LL_GPIO_PIN_13
MotorControl.OPAMP2_NONINVERTINGINPUT_PHB_GPIO_PORT=GPIOA
MotorControl.OPAMP2_NONINVERTINGINPUT_PHB_GPIO_PORT2=GPIOB
MotorControl.OPAMP2_NONINVERTINGINPUT_PHC=OPAMP2_NonInvertingInput_PB14
MotorControl.OPAMP2_NONINVERTINGINPUT_PHC2=OPAMP4_NonInvertingInput_PB11
MotorControl.OPAMP2_NONINVERTINGINPUT_PHC_GPIO_PIN=LL_GPIO_PIN_14
MotorControl.OPAMP2_NONINVERTINGINPUT_PHC_GPIO_PIN2=LL_GPIO_PIN_11
MotorControl.OPAMP2_NONINVERTINGINPUT_PHC_GPIO_PORT=GPIOB
MotorControl.OPAMP2_NONINVERTINGINPUT_PHC_GPIO_PORT2=GPIOB
MotorControl.OPAMP2_OUT_GPIO_PIN=LL_GPIO_PIN_6
MotorControl.OPAMP2_OUT_GPIO_PIN2=LL_GPIO_PIN_12
MotorControl.OPAMP2_OUT_GPIO_PORT=GPIOA
MotorControl.OPAMP2_OUT_GPIO_PORT2=GPIOB
MotorControl.OPAMP2_SELECTION=OPAMP2
MotorControl.OPAMP2_SELECTION2=OPAMP4
MotorControl.OPAMP_INVERTINGINPUT=OPAMP1_InvertingInput_PGA
MotorControl.OPAMP_INVERTINGINPUT2=OPAMP3_InvertingInput_PGA
MotorControl.OPAMP_INVERTINGINPUT_GPIO_PIN=LL_GPIO_PIN_3
MotorControl.OPAMP_INVERTINGINPUT_GPIO_PIN2=LL_GPIO_PIN_2
MotorControl.OPAMP_INVERTINGINPUT_GPIO_PORT=GPIOA
MotorControl.OPAMP_INVERTINGINPUT_GPIO_PORT2=GPIOB
MotorControl.OPAMP_INVERTINGINPUT_MODE=INT_MODE
MotorControl.OPAMP_INVERTINGINPUT_MODE2=INT_MODE
MotorControl.OPAMP_NONINVERTINGINPUT=OPAMP1_NonInvertingInput_PA7
MotorControl.OPAMP_NONINVERTINGINPUT2=OPAMP3_NonInvertingInput_PB13
MotorControl.OPAMP_NONINVERTINGINPUT_GPIO_PIN=LL_GPIO_PIN_7
MotorControl.OPAMP_NONINVERTINGINPUT_GPIO_PIN2=LL_GPIO_PIN_13
MotorControl.OPAMP_NONINVERTINGINPUT_GPIO_PORT=GPIOA
MotorControl.OPAMP_NONINVERTINGINPUT_GPIO_PORT2=GPIOB
MotorControl.OPAMP_OUT_GPIO_PIN=LL_GPIO_PIN_2
MotorControl.OPAMP_OUT_GPIO_PIN2=LL_GPIO_PIN_1
MotorControl.OPAMP_OUT_GPIO_PORT=GPIOA
MotorControl.OPAMP_OUT_GPIO_PORT2=GPIOB
MotorControl.OPAMP_PGACONNECT=OPAMP_PGAConnect_No
MotorControl.OPAMP_PGACONNECT2=OPAMP_PGAConnect_No
MotorControl.OPAMP_PGAGAIN=OPAMP_OPAMP_PGAGain_2
MotorControl.OPAMP_PGAGAIN2=OPAMP_OPAMP_PGAGain_2
MotorControl.OPAMP_SELECTION=OPAMP1
MotorControl.OPAMP_SELECTION2=OPAMP3
MotorControl.OPAMP_TYPE_GAIN=INTERNAL
MotorControl.OPAMP_TYPE_GAIN2=INTERNAL
MotorControl.OPEN_LOOP_FOC=false
MotorControl.OPEN_LOOP_FOC2=false
MotorControl.OPEN_LOOP_K=44
MotorControl.OPEN_LOOP_K2=44
MotorControl.OPEN_LOOP_OFF=4400
MotorControl.OPEN_LOOP_OFF2=4400
MotorControl.OPEN_LOOP_SPEED_RAMP_DURATION_MS=1000
MotorControl.OPEN_LOOP_SPEED_RAMP_DURATION_MS2=1000
MotorControl.OPEN_LOOP_SPEED_RPM=100
MotorControl.OPEN_LOOP_SPEED_RPM2=100
MotorControl.OPEN_LOOP_VF=false
MotorControl.OPEN_LOOP_VF2=false
MotorControl.OPEN_LOOP_VOLTAGE_d=6000
MotorControl.OPEN_LOOP_VOLTAGE_d2=6000
MotorControl.OVERCURR_FEEDBACK_POLARITY=EMSTOP2_ACTIVE_LOW
MotorControl.OVERCURR_FEEDBACK_POLARITY2=EMSTOP2_ACTIVE_LOW
MotorControl.OVERCURR_PROTECTION_HW_DISABLING=DOUT_ACTIVE_HIGH
MotorControl.OVERCURR_PROTECTION_HW_DISABLING2=DOUT_ACTIVE_HIGH
MotorControl.OVPREF=23830
MotorControl.OVPREF2=23830
MotorControl.OVP_FILTER=COMP_Mode_HighSpeed
MotorControl.OVP_FILTER2=COMP_Mode_HighSpeed
MotorControl.OVP_INVERTINGINPUT=COMPX_InvertingInput_VREF
MotorControl.OVP_INVERTINGINPUT2=COMPX_InvertingInput_VREF
MotorControl.OVP_INVERTINGINPUT_GPIO_PIN=LL_GPIO_PIN_4
MotorControl.OVP_INVERTINGINPUT_GPIO_PIN2=LL_GPIO_PIN_4
MotorControl.OVP_INVERTINGINPUT_GPIO_PORT=GPIOA
MotorControl.OVP_INVERTINGINPUT_GPIO_PORT2=GPIOA
MotorControl.OVP_INVERTINGINPUT_MODE=INT_MODE
MotorControl.OVP_INVERTINGINPUT_MODE2=INT_MODE
MotorControl.OVP_NONINVERTINGINPUT=COMP1_NonInvertingInput_PA1
MotorControl.OVP_NONINVERTINGINPUT2=COMP1_NonInvertingInput_PA1
MotorControl.OVP_NONINVERTINGINPUT_GPIO_PIN=LL_GPIO_PIN_1
MotorControl.OVP_NONINVERTINGINPUT_GPIO_PIN2=LL_GPIO_PIN_1
MotorControl.OVP_NONINVERTINGINPUT_GPIO_PORT=GPIOA
MotorControl.OVP_NONINVERTINGINPUT_GPIO_PORT2=GPIOA
MotorControl.OVP_OUTPUT=COMP_Output_TIM1BKIN
MotorControl.OVP_OUTPUT2=COMP_Output_TIM8BKIN
MotorControl.OVP_OUTPUTPOL=COMP_OutputPol_NonInverted
MotorControl.OVP_OUTPUTPOL2=COMP_OutputPol_NonInverted
MotorControl.OVP_OUTPUT_GPIO_AF=GPIO_AF_8
MotorControl.OVP_OUTPUT_GPIO_AF2=GPIO_AF_8
MotorControl.OVP_OUTPUT_GPIO_PIN=LL_GPIO_PIN_0
MotorControl.OVP_OUTPUT_GPIO_PIN2=LL_GPIO_PIN_0
MotorControl.OVP_OUTPUT_GPIO_PORT=GPIOA
MotorControl.OVP_OUTPUT_GPIO_PORT2=GPIOA
MotorControl.OVP_OUTPUT_MODE=EXT_MODE
MotorControl.OVP_OUTPUT_MODE2=EXT_MODE
MotorControl.OVP_SELECTION=COMP1
MotorControl.OVP_SELECTION2=COMP1
MotorControl.OV_CURR_BYPASS_GPIO_PIN=LL_GPIO_PIN_5
MotorControl.OV_CURR_BYPASS_GPIO_PIN2=LL_GPIO_PIN_10
MotorControl.OV_CURR_BYPASS_GPIO_PORT=GPIOE
MotorControl.OV_CURR_BYPASS_GPIO_PORT2=GPIOF
MotorControl.OV_TEMPERATURE_HYSTERESIS_C=10
MotorControl.OV_TEMPERATURE_HYSTERESIS_C2=10
MotorControl.OV_TEMPERATURE_PROT_ENABLING=false
MotorControl.OV_TEMPERATURE_PROT_ENABLING2=true
MotorControl.OV_TEMPERATURE_THRESHOLD_C=70
MotorControl.OV_TEMPERATURE_THRESHOLD_C2=70
MotorControl.OV_VOLTAGE_PROT_ENABLING=true
MotorControl.OV_VOLTAGE_PROT_ENABLING2=true
MotorControl.OV_VOLTAGE_THRESHOLD_V=32
MotorControl.OV_VOLTAGE_THRESHOLD_V2=32
MotorControl.PHASE1_DURATION=1000
MotorControl.PHASE1_DURATION2=1000
MotorControl.PHASE1_FINAL_CURRENT=20300
MotorControl.PHASE1_FINAL_CURRENT2=20300
MotorControl.PHASE1_FINAL_SPEED_RPM=0
MotorControl.PHASE1_FINAL_SPEED_RPM2=0
MotorControl.PHASE2_DURATION=1600
MotorControl.PHASE2_DURATION2=1600
MotorControl.PHASE2_FINAL_CURRENT=20300
MotorControl.PHASE2_FINAL_CURRENT2=20300
MotorControl.PHASE2_FINAL_SPEED_RPM=1600
MotorControl.PHASE2_FINAL_SPEED_RPM2=1600
MotorControl.PHASE3_DURATION=0
MotorControl.PHASE3_DURATION2=0
MotorControl.PHASE3_FINAL_CURRENT=20300
MotorControl.PHASE3_FINAL_CURRENT2=20300
MotorControl.PHASE3_FINAL_SPEED_RPM=1600
MotorControl.PHASE3_FINAL_SPEED_RPM2=1600
MotorControl.PHASE4_DURATION=0
MotorControl.PHASE4_DURATION2=0
MotorControl.PHASE4_FINAL_CURRENT=20300
MotorControl.PHASE4_FINAL_CURRENT2=20300
MotorControl.PHASE4_FINAL_SPEED_RPM=1600
MotorControl.PHASE4_FINAL_SPEED_RPM2=1600
MotorControl.PHASE5_DURATION=0
MotorControl.PHASE5_DURATION2=0
MotorControl.PHASE5_FINAL_CURRENT=20300
MotorControl.PHASE5_FINAL_CURRENT2=20300
MotorControl.PHASE5_FINAL_SPEED_RPM=1600
MotorControl.PHASE5_FINAL_SPEED_RPM2=1600
MotorControl.PHASE_CURRENTS_ADC=ADC1_2
MotorControl.PHASE_CURRENTS_ADC2=ADC3
MotorControl.PHASE_CURRENTS_CHANNEL=ADC_CHANNEL_9
MotorControl.PHASE_CURRENTS_CHANNEL2=ADC_CHANNEL_1
MotorControl.PHASE_CURRENTS_GPIO_PIN=LL_GPIO_PIN_3
MotorControl.PHASE_CURRENTS_GPIO_PIN2=LL_GPIO_PIN_1
MotorControl.PHASE_CURRENTS_GPIO_PORT=GPIOC
MotorControl.PHASE_CURRENTS_GPIO_PORT2=GPIOB
MotorControl.PHASE_UH_GPIO_AF=GPIO_AF_2
MotorControl.PHASE_UH_GPIO_AF2=GPIO_AF_4
MotorControl.PHASE_UH_GPIO_PIN=LL_GPIO_PIN_9
MotorControl.PHASE_UH_GPIO_PIN2=LL_GPIO_PIN_6
MotorControl.PHASE_UH_GPIO_PORT=GPIOE
MotorControl.PHASE_UH_GPIO_PORT2=GPIOC
MotorControl.PHASE_UH_POLARITY=H_ACTIVE_HIGH
MotorControl.PHASE_UH_POLARITY2=H_ACTIVE_HIGH
MotorControl.PHASE_UL_GPIO_AF=GPIO_AF_2
MotorControl.PHASE_UL_GPIO_AF2=GPIO_AF_4
MotorControl.PHASE_UL_GPIO_PIN=LL_GPIO_PIN_8
MotorControl.PHASE_UL_GPIO_PIN2=LL_GPIO_PIN_10
MotorControl.PHASE_UL_GPIO_PORT=GPIOE
MotorControl.PHASE_UL_GPIO_PORT2=GPIOC
MotorControl.PHASE_UL_POLARITY=L_ACTIVE_HIGH
MotorControl.PHASE_UL_POLARITY2=L_ACTIVE_HIGH
MotorControl.PHASE_U_CURR_ADC=ADC1
MotorControl.PHASE_U_CURR_ADC2=ADC3
MotorControl.PHASE_U_CURR_CHANNEL=ADC_CHANNEL_3
MotorControl.PHASE_U_CURR_CHANNEL2=ADC_CHANNEL_1
MotorControl.PHASE_U_GPIO_PIN=LL_GPIO_PIN_2
MotorControl.PHASE_U_GPIO_PIN2=LL_GPIO_PIN_1
MotorControl.PHASE_U_GPIO_PORT=GPIOA
MotorControl.PHASE_U_GPIO_PORT2=GPIOB
MotorControl.PHASE_VH_GPIO_AF=GPIO_AF_2
MotorControl.PHASE_VH_GPIO_AF2=GPIO_AF_4
MotorControl.PHASE_VH_GPIO_PIN=LL_GPIO_PIN_11
MotorControl.PHASE_VH_GPIO_PIN2=LL_GPIO_PIN_7
MotorControl.PHASE_VH_GPIO_PORT=GPIOE
MotorControl.PHASE_VH_GPIO_PORT2=GPIOC
MotorControl.PHASE_VH_POLARITY=H_ACTIVE_HIGH
MotorControl.PHASE_VH_POLARITY2=H_ACTIVE_HIGH
MotorControl.PHASE_VL_GPIO_AF=GPIO_AF_2
MotorControl.PHASE_VL_GPIO_AF2=GPIO_AF_4
MotorControl.PHASE_VL_GPIO_PIN=LL_GPIO_PIN_10
MotorControl.PHASE_VL_GPIO_PIN2=LL_GPIO_PIN_11
MotorControl.PHASE_VL_GPIO_PORT=GPIOE
MotorControl.PHASE_VL_GPIO_PORT2=GPIOC
MotorControl.PHASE_VL_POLARITY=L_ACTIVE_HIGH
MotorControl.PHASE_VL_POLARITY2=L_ACTIVE_HIGH
MotorControl.PHASE_V_CURR_ADC=ADC2
MotorControl.PHASE_V_CURR_ADC2=ADC4
MotorControl.PHASE_V_CURR_CHANNEL=ADC_CHANNEL_3
MotorControl.PHASE_V_CURR_CHANNEL2=ADC_CHANNEL_3
MotorControl.PHASE_V_GPIO_PIN=LL_GPIO_PIN_6
MotorControl.PHASE_V_GPIO_PIN2=LL_GPIO_PIN_12
MotorControl.PHASE_V_GPIO_PORT=GPIOA
MotorControl.PHASE_V_GPIO_PORT2=GPIOB
MotorControl.PHASE_WH_GPIO_AF=GPIO_AF_2
MotorControl.PHASE_WH_GPIO_AF2=GPIO_AF_4
MotorControl.PHASE_WH_GPIO_PIN=LL_GPIO_PIN_13
MotorControl.PHASE_WH_GPIO_PIN2=LL_GPIO_PIN_8
MotorControl.PHASE_WH_GPIO_PORT=GPIOE
MotorControl.PHASE_WH_GPIO_PORT2=GPIOC
MotorControl.PHASE_WH_POLARITY=H_ACTIVE_HIGH
MotorControl.PHASE_WH_POLARITY2=H_ACTIVE_HIGH
MotorControl.PHASE_WL_GPIO_AF=GPIO_AF_2
MotorControl.PHASE_WL_GPIO_AF2=GPIO_AF_4
MotorControl.PHASE_WL_GPIO_PIN=LL_GPIO_PIN_12
MotorControl.PHASE_WL_GPIO_PIN2=LL_GPIO_PIN_12
MotorControl.PHASE_WL_GPIO_PORT=GPIOE
MotorControl.PHASE_WL_GPIO_PORT2=GPIOC
MotorControl.PHASE_WL_POLARITY=L_ACTIVE_HIGH
MotorControl.PHASE_WL_POLARITY2=L_ACTIVE_HIGH
MotorControl.PHASE_W_CURR_ADC=ADC1_2
MotorControl.PHASE_W_CURR_ADC2=ADC3_4
MotorControl.PHASE_W_CURR_CHANNEL=ADC_CHANNEL_6
MotorControl.PHASE_W_CURR_CHANNEL2=ADC_CHANNEL_7
MotorControl.PHASE_W_GPIO_PIN=LL_GPIO_PIN_0
MotorControl.PHASE_W_GPIO_PIN2=LL_GPIO_PIN_10
MotorControl.PHASE_W_GPIO_PORT=GPIOC
MotorControl.PHASE_W_GPIO_PORT2=GPIOD
MotorControl.PID_FLUX_KD_DEFAULT=100
MotorControl.PID_FLUX_KD_DEFAULT2=100
MotorControl.PID_FLUX_KI_DEFAULT=463
MotorControl.PID_FLUX_KI_DEFAULT2=463
MotorControl.PID_FLUX_KP_DEFAULT=2975
MotorControl.PID_FLUX_KP_DEFAULT2=2975
MotorControl.PID_SPEED_KD_DEFAULT=0
MotorControl.PID_SPEED_KD_DEFAULT2=0
MotorControl.PID_SPEED_KI_DEFAULT=3502
MotorControl.PID_SPEED_KI_DEFAULT2=3502
MotorControl.PID_SPEED_KP_DEFAULT=2443
MotorControl.PID_SPEED_KP_DEFAULT2=2443
MotorControl.PID_TORQUE_KD_DEFAULT=100
MotorControl.PID_TORQUE_KD_DEFAULT2=100
MotorControl.PID_TORQUE_KI_DEFAULT=463
MotorControl.PID_TORQUE_KI_DEFAULT2=463
MotorControl.PID_TORQUE_KP_DEFAULT=2975
MotorControl.PID_TORQUE_KP_DEFAULT2=2975
MotorControl.PLL_KI_GAIN=13
MotorControl.PLL_KI_GAIN2=13
MotorControl.PLL_KP_GAIN=284
MotorControl.PLL_KP_GAIN2=284
MotorControl.POLE_PAIR_NUM=2
MotorControl.POLE_PAIR_NUM2=2
MotorControl.PWBDID=22
MotorControl.PWBDID2=22
MotorControl.PWM_FREQUENCY=15000
MotorControl.PWM_FREQUENCY2=15000
MotorControl.PWM_TIMER_REMAPPING=PWM_NO_REMAP
MotorControl.PWM_TIMER_REMAPPING2=PWM_NO_REMAP
MotorControl.PWM_TIMER_SELECTION=PWM_TIM1
MotorControl.PWM_TIMER_SELECTION2=PWM_TIM8
MotorControl.REGCONVADC=ADC1
MotorControl.REGCONVADC2=ADC1
MotorControl.REGULATION_EXECUTION_RATE=1
MotorControl.REGULATION_EXECUTION_RATE2=1
MotorControl.RS=0.35
MotorControl.RS2=0.35
MotorControl.RSHUNT=0.470
MotorControl.RSHUNT2=0.470
MotorControl.R_BRAKE_GPIO_PIN=LL_GPIO_PIN_5
MotorControl.R_BRAKE_GPIO_PIN2=LL_GPIO_PIN_10
MotorControl.R_BRAKE_GPIO_PORT=GPIOE
MotorControl.R_BRAKE_GPIO_PORT2=GPIOF
MotorControl.R_BRAKE_SWITCH_OFF_THRES_V=26
MotorControl.R_BRAKE_SWITCH_OFF_THRES_V2=26
MotorControl.SEGDIV=0
MotorControl.SEGDIV2=0
MotorControl.SERIAL_COMMUNICATION=true
MotorControl.SERIAL_COMMUNICATION2=true
MotorControl.SERIAL_COM_CHANNEL1=MC_PROTOCOL_REG_I_A
MotorControl.SERIAL_COM_CHANNEL12=MC_PROTOCOL_REG_I_A
MotorControl.SERIAL_COM_CHANNEL2=MC_PROTOCOL_REG_I_A
MotorControl.SERIAL_COM_CHANNEL22=MC_PROTOCOL_REG_I_A
MotorControl.SERIAL_COM_MODE=COM_BIDIRECTIONAL
MotorControl.SERIAL_COM_MODE2=COM_BIDIRECTIONAL
MotorControl.SERIAL_COM_MOTOR=0
MotorControl.SERIAL_COM_MOTOR2=0
MotorControl.SHARED_SIGNAL_ENABLE=false
MotorControl.SHARED_SIGNAL_ENABLE2=false
MotorControl.SPD_DIFFERENTIAL_TERM_ENABLING=false
MotorControl.SPD_DIFFERENTIAL_TERM_ENABLING2=false
MotorControl.SPEED_BAND_LOWER_LIMIT=15
MotorControl.SPEED_BAND_LOWER_LIMIT2=15
MotorControl.SPEED_BAND_UPPER_LIMIT=17
MotorControl.SPEED_BAND_UPPER_LIMIT2=17
MotorControl.SPEED_FEEDBACK_CHECK=true
MotorControl.SPEED_FEEDBACK_CHECK2=true
MotorControl.SPEED_LOOP_FREQUENCY_HZ=500
MotorControl.SPEED_LOOP_FREQUENCY_HZ2=500
MotorControl.SPEED_SENSOR_SELECTION=STATE_OBSERVER_PLL
MotorControl.SPEED_SENSOR_SELECTION2=STATE_OBSERVER_PLL2
MotorControl.SP_KDDIV=16
MotorControl.SP_KDDIV2=16
MotorControl.SP_KIDIV=8192
MotorControl.SP_KIDIV2=8192
MotorControl.SP_KPDIV=32
MotorControl.SP_KPDIV2=32
MotorControl.STARTING_ANGLE_DEG=0
MotorControl.STARTING_ANGLE_DEG2=0
MotorControl.START_STOP_BTN=true
MotorControl.START_STOP_BTN2=true
MotorControl.START_STOP_GPIO_PIN=LL_GPIO_PIN_6
MotorControl.START_STOP_GPIO_PIN2=LL_GPIO_PIN_6
MotorControl.START_STOP_GPIO_PORT=GPIOE
MotorControl.START_STOP_GPIO_PORT2=GPIOE
MotorControl.START_STOP_POLARITY=DIN_ACTIVE_LOW
MotorControl.START_STOP_POLARITY2=DIN_ACTIVE_LOW
MotorControl.STATE_OBSERVER_PLL=true
MotorControl.STATE_OBSERVER_PLL2=true
MotorControl.STM32F303xC=true
MotorControl.STO_FIFO_DEPTH_01HZ=64
MotorControl.STO_FIFO_DEPTH_01HZ2=64
MotorControl.STO_FIFO_DEPTH_DPP=64
MotorControl.STO_FIFO_DEPTH_DPP2=64
MotorControl.STO_HFI_RPM_TH=460
MotorControl.STO_HFI_RPM_TH2=460
MotorControl.SW_DEADTIME_NS=1500
MotorControl.SW_DEADTIME_NS2=1500
MotorControl.SW_OV_CURRENT_PROT_ENABLING=true
MotorControl.SW_OV_CURRENT_PROT_ENABLING2=true
MotorControl.T0_C=25
MotorControl.T0_C2=25
MotorControl.TEMPERATURE_READING=false
MotorControl.TEMPERATURE_READING2=true
MotorControl.TEMP_ADC_SAMPLING_TIME=61
MotorControl.TEMP_ADC_SAMPLING_TIME2=61
MotorControl.TEMP_FDBK_ADC=ADC1
MotorControl.TEMP_FDBK_ADC2=ADC1_2
MotorControl.TEMP_FDBK_CHANNEL=ADC_CHANNEL_5
MotorControl.TEMP_FDBK_CHANNEL2=ADC_CHANNEL_10
MotorControl.TEMP_FDBK_GPIO_PIN=LL_GPIO_PIN_4
MotorControl.TEMP_FDBK_GPIO_PIN2=LL_GPIO_PIN_2
MotorControl.TEMP_FDBK_GPIO_PORT=GPIOF
MotorControl.TEMP_FDBK_GPIO_PORT2=GPIOF
MotorControl.TFDIFFERENTIAL_TERM_ENABLING=false
MotorControl.TFDIFFERENTIAL_TERM_ENABLING2=false
MotorControl.TF_KDDIV=8192
MotorControl.TF_KDDIV2=8192
MotorControl.TF_KIDIV=16384
MotorControl.TF_KIDIV2=16384
MotorControl.TF_KPDIV=4096
MotorControl.TF_KPDIV2=4096
MotorControl.THREE_SHUNT_INDEPENDENT_RESOURCES=true
MotorControl.THREE_SHUNT_INDEPENDENT_RESOURCES2=true
MotorControl.TNOISE_NS=300
MotorControl.TNOISE_NS2=300
MotorControl.TRANSITION_DURATION=25
MotorControl.TRANSITION_DURATION2=25
MotorControl.TRISE_NS=2250
MotorControl.TRISE_NS2=2250
MotorControl.T_MAX=70
MotorControl.T_MAX2=70
MotorControl.UD_VOLTAGE_THRESHOLD_V=18
MotorControl.UD_VOLTAGE_THRESHOLD_V2=18
MotorControl.USART_REMAPPING=NO_REMAP_USART1
MotorControl.USART_REMAPPING2=NO_REMAP_USART1
MotorControl.USART_RX_GPIO_PIN=LL_GPIO_PIN_1
MotorControl.USART_RX_GPIO_PIN2=LL_GPIO_PIN_1
MotorControl.USART_RX_GPIO_PORT=GPIOE
MotorControl.USART_RX_GPIO_PORT2=GPIOE
MotorControl.USART_SELECTION=USE_USART1
MotorControl.USART_SELECTION2=USE_USART1
MotorControl.USART_SPEED=115200
MotorControl.USART_SPEED2=115200
MotorControl.USART_TX_GPIO_PIN=LL_GPIO_PIN_4
MotorControl.USART_TX_GPIO_PIN2=LL_GPIO_PIN_4
MotorControl.USART_TX_GPIO_PORT=GPIOC
MotorControl.USART_TX_GPIO_PORT2=GPIOC
MotorControl.USE_INTERNAL_OPAMP=true
MotorControl.USE_INTERNAL_OPAMP2=true
MotorControl.UV_VOLTAGE_PROT_ENABLING=true
MotorControl.UV_VOLTAGE_PROT_ENABLING2=true
MotorControl.V0_V=1.055
MotorControl.V0_V2=1.055
MotorControl.VARIANCE_THRESHOLD=0.3
MotorControl.VARIANCE_THRESHOLD2=0.3
MotorControl.VBUS_ADC=ADC1
MotorControl.VBUS_ADC2=ADC1_2
MotorControl.VBUS_ADC_SAMPLING_TIME=61
MotorControl.VBUS_ADC_SAMPLING_TIME2=61
MotorControl.VBUS_CHANNEL=ADC_CHANNEL_1
MotorControl.VBUS_CHANNEL2=ADC_CHANNEL_7
MotorControl.VBUS_GPIO_PIN=LL_GPIO_PIN_0
MotorControl.VBUS_GPIO_PIN2=LL_GPIO_PIN_1
MotorControl.VBUS_GPIO_PORT=GPIOA
MotorControl.VBUS_GPIO_PORT2=GPIOC
MotorControl.VBUS_PARTITIONING_FACTOR=0.0086
MotorControl.VBUS_PARTITIONING_FACTOR2=0.0086
MotorControl.dV_dT=0.022
MotorControl.dV_dT2=0.022
NVIC.ADC1_2_IRQn=true\:2\:0\:true\:true\:false\:2\:true
NVIC.ADC3_IRQn=true\:2\:0\:true\:true\:false\:4\:true
NVIC.EXTI9_5_IRQn=true\:0\:0\:false\:true\:false\:6\:true
NVIC.PriorityGroup=NVIC_PRIORITYGROUP_3
NVIC.TIM1_BRK_TIM15_IRQn=true\:4\:1\:true\:true\:false\:1\:true
NVIC.TIM8_BRK_IRQn=true\:4\:1\:true\:true\:false\:3\:true
NVIC.USART1_IRQn=true\:3\:1\:true\:true\:false\:5\:true
OPAMP1.PgaGain=OPAMP_PGA_GAIN_2
OPAMP1.SelfCalibration=Disable
OPAMP2.PgaGain=OPAMP_PGA_GAIN_2
OPAMP2.SelfCalibration=Disable
OPAMP3.PgaGain=OPAMP_PGA_GAIN_2
OPAMP3.SelfCalibration=Disable
OPAMP4.PgaGain=OPAMP_PGA_GAIN_2
OPAMP4.SelfCalibration=Disable
PA0.GPIO_Label=M1_BUS_VOLTAGE
PA0.Mode=IN1-Single-Ended
PA0.Signal=ADC1_IN1
PA1.GPIO_Label=M1_CURR_SHUNT_U
PA1.Signal=SharedAnalog_PA1
PA2.GPIO_Label=M1_OPAMP1_OUT
PA2.Signal=SharedAnalog_PA2
PA4.GPIO_Label=M1_2_OCP_DAC_CH1_REF
PA4.Signal=SharedAnalog_PA4
PA5.GPIO_Label=DBG_DAC_CH2
PA5.Signal=COMP_DAC12_group
PA6.GPIO_Label=M1_OPAMP2_OUT
PA6.Signal=SharedAnalog_PA6
PA7.GPIO_Label=M1_CURR_SHUNT_V
PA7.Signal=SharedAnalog_PA7
PB0.GPIO_Label=M2_CURR_SHUNT_U
PB0.Signal=SharedAnalog_PB0
PB1.GPIO_Label=M2_OPAMP3_OUT
PB1.Signal=SharedAnalog_PB1
PB11.GPIO_Label=M2_CURR_SHUNT_W
PB11.Signal=SharedAnalog_PB11
PB12.GPIO_Label=M2_OPAMP4_OUT
PB12.Signal=SharedAnalog_PB12
PB13.GPIO_Label=M2_CURR_SHUNT_V
PB13.Signal=SharedAnalog_PB13
PB14.GPIO_Label=M1_CURR_SHUNT_W
PB14.Signal=SharedAnalog_PB14
PC1.GPIO_Label=M2_BUS_VOLTAGE
PC1.Signal=ADCx_IN7
PC10.GPIO_Label=M2_PWM_UL
PC10.GPIO_PuPd=GPIO_PULLDOWN
PC10.GPIO_Speed=GPIO_SPEED_FREQ_HIGH
PC10.Mode=PWM Generation1 CH1 CH1N
PC10.Signal=TIM8_CH1N
PC11.GPIO_Label=M2_PWM_VL
PC11.GPIO_PuPd=GPIO_PULLDOWN
PC11.GPIO_Speed=GPIO_SPEED_FREQ_HIGH
PC11.Mode=PWM Generation2 CH2 CH2N
PC11.Signal=TIM8_CH2N
PC12.GPIO_Label=M2_PWM_WL
PC12.GPIO_PuPd=GPIO_PULLDOWN
PC12.GPIO_Speed=GPIO_SPEED_FREQ_HIGH
PC12.Mode=PWM Generation3 CH3 CH3N
PC12.Signal=TIM8_CH3N
PC4.GPIO_Label=UART_TX
PC4.GPIO_Mode=GPIO_MODE_AF_PP
PC4.GPIO_PuPd=GPIO_NOPULL
PC4.GPIO_Speed=GPIO_SPEED_FREQ_LOW
PC4.Mode=Asynchronous
PC4.Signal=USART1_TX
PC6.GPIO_Label=M2_PWM_UH
PC6.GPIO_PuPd=GPIO_PULLDOWN
PC6.GPIO_Speed=GPIO_SPEED_FREQ_HIGH
PC6.Signal=S_TIM8_CH1
PC7.GPIO_Label=M2_PWM_VH
PC7.GPIO_PuPd=GPIO_PULLDOWN
PC7.GPIO_Speed=GPIO_SPEED_FREQ_HIGH
PC7.Signal=S_TIM8_CH2
PC8.GPIO_Label=M2_PWM_WH
PC8.GPIO_PuPd=GPIO_PULLDOWN
PC8.GPIO_Speed=GPIO_SPEED_FREQ_HIGH
PC8.Signal=S_TIM8_CH3
PE1.GPIO_Label=UART_RX
PE1.GPIO_Mode=GPIO_MODE_AF_PP
PE1.GPIO_PuPd=GPIO_NOPULL
PE1.GPIO_Speed=GPIO_SPEED_FREQ_LOW
PE1.Mode=Asynchronous
PE1.Signal=USART1_RX
PE10.GPIO_Label=M1_PWM_VL
PE10.GPIO_PuPd=GPIO_PULLDOWN
PE10.GPIO_Speed=GPIO_SPEED_FREQ_HIGH
PE10.Mode=PWM Generation2 CH2 CH2N
PE10.Signal=TIM1_CH2N
PE11.GPIO_Label=M1_PWM_VH
PE11.GPIO_PuPd=GPIO_PULLDOWN
PE11.GPIO_Speed=GPIO_SPEED_FREQ_HIGH
PE11.Signal=S_TIM1_CH2
PE12.GPIO_Label=M1_PWM_WL
PE12.GPIO_PuPd=GPIO_PULLDOWN
PE12.GPIO_Speed=GPIO_SPEED_FREQ_HIGH
PE12.Mode=PWM Generation3 CH3 CH3N
PE12.Signal=TIM1_CH3N
PE13.GPIO_Label=M1_PWM_WH
PE13.GPIO_PuPd=GPIO_PULLDOWN
PE13.GPIO_Speed=GPIO_SPEED_FREQ_HIGH
PE13.Signal=S_TIM1_CH3
PE6.GPIO_Label=Start/Stop [PushButton]
PE6.GPIO_ModeDefaultEXTI=GPIO_MODE_IT_FALLING
PE6.Signal=GPXTI6
PE8.GPIO_Label=M1_PWM_UL
PE8.GPIO_PuPd=GPIO_PULLDOWN
PE8.GPIO_Speed=GPIO_SPEED_FREQ_HIGH
PE8.Mode=PWM Generation1 CH1 CH1N
PE8.Signal=TIM1_CH1N
PE9.GPIO_Label=M1_PWM_UH
PE9.GPIO_PuPd=GPIO_PULLDOWN
PE9.GPIO_Speed=GPIO_SPEED_FREQ_HIGH
PE9.Signal=S_TIM1_CH1
PF0-OSC_IN.Mode=HSE-External-Oscillator
PF0-OSC_IN.Signal=RCC_OSC_IN
PF1-OSC_OUT.Mode=HSE-External-Oscillator
PF1-OSC_OUT.Signal=RCC_OSC_OUT
PF2.GPIO_Label=M2_TEMPERATURE
PF2.Signal=ADCx_IN10
ProjectManager.HeapSize=0x200
ProjectManager.StackSize=0x400
ProjectManager.TargetToolchain=TrueSTUDIO
RCC.AHBFreq_Value=72000000
RCC.APB1CLKDivider=RCC_HCLK_DIV2
RCC.APB1Freq_Value=36000000
RCC.APB1TimFreq_Value=72000000
RCC.APB2Freq_Value=72000000
RCC.APB2TimFreq_Value=72000000
RCC.CortexFreq_Value=72000000
RCC.EnbaleCSS=true
RCC.HCLKFreq_Value=72000000
RCC.HSE_VALUE=8000000
RCC.HSI_VALUE=8000000
RCC.LSE_VALUE=32768
RCC.PLLMUL=RCC_PLL_MUL9
RCC.PLLSourceVirtual=RCC_PLLSOURCE_HSE
RCC.SYSCLKFreq_VALUE=72000000
RCC.SYSCLKSourceVirtual=RCC_SYSCLKSOURCE_PLLCLK
RCC.USBFreq_Value=72000000
SH.ADCx_IN10.0=ADC1_IN10,IN10-Single-Ended
SH.ADCx_IN7.0=ADC1_IN7,IN7-Single-Ended
SH.COMP_DAC12_group.0=DAC1_OUT2,Enable_DAC_OUT2
SH.S_TIM1_CH1.0=TIM1_CH1,PWM Generation1 CH1 CH1N
SH.S_TIM1_CH2.0=TIM1_CH2,PWM Generation2 CH2 CH2N
SH.S_TIM1_CH3.0=TIM1_CH3,PWM Generation3 CH3 CH3N
SH.S_TIM8_CH1.0=TIM8_CH1,PWM Generation1 CH1 CH1N
SH.S_TIM8_CH2.0=TIM8_CH2,PWM Generation2 CH2 CH2N
SH.S_TIM8_CH3.0=TIM8_CH3,PWM Generation3 CH3 CH3N
SH.SharedAnalog_PA1.0=COMP1_INP,INP
SH.SharedAnalog_PA1.1=OPAMP1_VINP,PGA Not Connected
SH.SharedAnalog_PA2.0=OPAMP1_VOUT,PGA Not Connected
SH.SharedAnalog_PA2.1=ADC1_IN3,IN3-Single-Ended
SH.SharedAnalog_PA4.0=COMP1_INM,INM
SH.SharedAnalog_PA4.1=COMP2_INM,INM
SH.SharedAnalog_PA4.2=COMP3_INM,INM
SH.SharedAnalog_PA4.3=COMP4_INM,INM
SH.SharedAnalog_PA4.4=COMP5_INM,INM
SH.SharedAnalog_PA4.5=COMP6_INM,INM
SH.SharedAnalog_PA4.6=DAC1_OUT1,DAC_OUT1
SH.SharedAnalog_PA6.0=OPAMP2_VOUT,PGA Not Connected
SH.SharedAnalog_PA6.1=ADC2_IN3,IN3-Single-Ended
SH.SharedAnalog_PA7.0=COMP2_INP,INP
SH.SharedAnalog_PA7.1=OPAMP2_VINP,PGA Not Connected
SH.SharedAnalog_PB0.0=COMP4_INP,INP
SH.SharedAnalog_PB0.1=OPAMP3_VINP,PGA Not Connected
SH.SharedAnalog_PB1.0=OPAMP3_VOUT,PGA Not Connected
SH.SharedAnalog_PB1.1=ADC3_IN1,IN1-Single-Ended
SH.SharedAnalog_PB11.0=OPAMP4_VINP_SEC
SH.SharedAnalog_PB11.1=COMP6_INP,INP
SH.SharedAnalog_PB12.0=OPAMP4_VOUT,PGA Not Connected
SH.SharedAnalog_PB12.1=ADC4_IN3,IN3-Single-Ended
SH.SharedAnalog_PB13.0=COMP5_INP,INP
SH.SharedAnalog_PB13.1=OPAMP4_VINP,PGA Not Connected
SH.SharedAnalog_PB14.0=OPAMP2_VINP_SEC
SH.SharedAnalog_PB14.1=COMP3_INP,INP
TIM1.AutoReloadPreload=TIM_AUTORELOAD_PRELOAD_DISABLE
TIM1.AutomaticOutput=TIM_AUTOMATICOUTPUT_DISABLE
TIM1.Break2Filter=4
TIM1.Break2Polarity=TIM_BREAK2POLARITY_HIGH
TIM1.Break2State=TIM_BREAK2_ENABLE
TIM1.BreakFilter=0
TIM1.BreakPolarity=TIM_BREAKPOLARITY_HIGH
TIM1.BreakState=TIM_BREAK_ENABLE
TIM1.Channel=TIM_CHANNEL_4
TIM1.Channel-PWM\ Generation1\ CH1\ CH1N=TIM_CHANNEL_1
TIM1.Channel-PWM\ Generation2\ CH2\ CH2N=TIM_CHANNEL_2
TIM1.Channel-PWM\ Generation3\ CH3\ CH3N=TIM_CHANNEL_3
TIM1.Channel-PWM\ Generation4\ No\ Output=TIM_CHANNEL_4
TIM1.ClearInputSource=TIM_CLEARINPUTSOURCE_NONE
TIM1.ClockDivision=TIM_CLOCKDIVISION_DIV2
TIM1.CounterMode=TIM_COUNTERMODE_CENTERALIGNED1
TIM1.DeadTime=((DEAD_TIME_COUNTS) / 2)
TIM1.LockLevel=TIM_LOCKLEVEL_1
TIM1.OCFastMode_PWM=TIM_OCFAST_DISABLE
TIM1.OCIdleState_1=TIM_OCIDLESTATE_RESET
TIM1.OCIdleState_2=TIM_OCIDLESTATE_RESET
TIM1.OCIdleState_3=TIM_OCIDLESTATE_RESET
TIM1.OCIdleState_4=TIM_OCIDLESTATE_RESET
TIM1.OCIdleState_5=TIM_OCIDLESTATE_RESET
TIM1.OCIdleState_6=TIM_OCIDLESTATE_RESET
TIM1.OCMode_PWM-PWM\ Generation1\ CH1\ CH1N=TIM_OCMODE_PWM1
TIM1.OCMode_PWM-PWM\ Generation2\ CH2\ CH2N=TIM_OCMODE_PWM1
TIM1.OCMode_PWM-PWM\ Generation3\ CH3\ CH3N=TIM_OCMODE_PWM1
TIM1.OCMode_PWM-PWM\ Generation4\ No\ Output=TIM_OCMODE_PWM2
TIM1.OCNIdleState_1=TIM_OCNIDLESTATE_RESET
TIM1.OCNIdleState_2=TIM_OCNIDLESTATE_RESET
TIM1.OCNIdleState_3=TIM_OCNIDLESTATE_RESET
TIM1.OCNPolarity_1=TIM_OCNPOLARITY_HIGH
TIM1.OCNPolarity_2=TIM_OCNPOLARITY_HIGH
TIM1.OCNPolarity_3=TIM_OCNPOLARITY_HIGH
TIM1.OCPolarity_1=TIM_OCPOLARITY_HIGH
TIM1.OCPolarity_2=TIM_OCPOLARITY_HIGH
TIM1.OCPolarity_3=TIM_OCPOLARITY_HIGH
TIM1.OCPolarity_4=TIM_OCPOLARITY_HIGH
TIM1.OCPolarity_5=TIM_OCPOLARITY_HIGH
TIM1.OCPolarity_6=TIM_OCPOLARITY_HIGH
TIM1.OffStateIDLEMode=TIM_OSSI_ENABLE
TIM1.OffStateRunMode=TIM_OSSR_ENABLE
TIM1.Period=((PWM_PERIOD_CYCLES) / 2)
TIM1.Prescaler=((TIM_CLOCK_DIVIDER) - 1)
TIM1.Pulse-PWM\ Generation1\ CH1=((PWM_PERIOD_CYCLES) / 4)
TIM1.Pulse-PWM\ Generation2\ CH2=((PWM_PERIOD_CYCLES) / 4)
TIM1.Pulse-PWM\ Generation3\ CH3=((PWM_PERIOD_CYCLES) / 4)
TIM1.Pulse-PWM\ Generation4\ No\ Output=(((PWM_PERIOD_CYCLES) / 2) - (HTMIN))
TIM1.Pulse-PWM\ Generation5\ No\ Output=(((PWM_PERIOD_CYCLES) / 2) + 1)
TIM1.Pulse-PWM\ Generation6\ No\ Output=(((PWM_PERIOD_CYCLES) / 2) + 1)
TIM1.RepetitionCounter=(REP_COUNTER)
TIM1.TIM_MasterOutputTrigger=TIM_TRGO_OC4REF
TIM1.TIM_MasterOutputTrigger2=TIM_TRGO2_RESET
TIM1.TIM_MasterSlaveMode=TIM_MASTERSLAVEMODE_DISABLE
TIM1.TIM_SlaveMode=TIM_SLAVEMODE_TRIGGER
TIM8.AutoReloadPreload=TIM_AUTORELOAD_PRELOAD_DISABLE
TIM8.AutomaticOutput=TIM_AUTOMATICOUTPUT_DISABLE
TIM8.Break2Filter=4
TIM8.Break2Polarity=TIM_BREAK2POLARITY_HIGH
TIM8.Break2State=TIM_BREAK2_ENABLE
TIM8.BreakFilter=0
TIM8.BreakPolarity=TIM_BREAKPOLARITY_HIGH
TIM8.BreakState=TIM_BREAK_ENABLE
TIM8.Channel=TIM_CHANNEL_4
TIM8.Channel-PWM\ Generation1\ CH1\ CH1N=TIM_CHANNEL_1
TIM8.Channel-PWM\ Generation2\ CH2\ CH2N=TIM_CHANNEL_2
TIM8.Channel-PWM\ Generation3\ CH3\ CH3N=TIM_CHANNEL_3
TIM8.Channel-PWM\ Generation4\ No\ Output=TIM_CHANNEL_4
TIM8.ClearInputSource=TIM_CLEARINPUTSOURCE_NONE
TIM8.ClockDivision=TIM_CLOCKDIVISION_DIV2
TIM8.CounterMode=TIM_COUNTERMODE_CENTERALIGNED1
TIM8.DeadTime=((DEAD_TIME_COUNTS) / 2)
TIM8.LockLevel=TIM_LOCKLEVEL_1
TIM8.OCFastMode_PWM=TIM_OCFAST_DISABLE
TIM8.OCIdleState_1=TIM_OCIDLESTATE_RESET
TIM8.OCIdleState_2=TIM_OCIDLESTATE_RESET
TIM8.OCIdleState_3=TIM_OCIDLESTATE_RESET
TIM8.OCIdleState_4=TIM_OCIDLESTATE_RESET
TIM8.OCIdleState_5=TIM_OCIDLESTATE_RESET
TIM8.OCIdleState_6=TIM_OCIDLESTATE_RESET
TIM8.OCMode_PWM-PWM\ Generation1\ CH1\ CH1N=TIM_OCMODE_PWM1
TIM8.OCMode_PWM-PWM\ Generation2\ CH2\ CH2N=TIM_OCMODE_PWM1
TIM8.OCMode_PWM-PWM\ Generation3\ CH3\ CH3N=TIM_OCMODE_PWM1
TIM8.OCMode_PWM-PWM\ Generation4\ No\ Output=TIM_OCMODE_PWM2
TIM8.OCNIdleState_1=TIM_OCNIDLESTATE_RESET
TIM8.OCNIdleState_2=TIM_OCNIDLESTATE_RESET
TIM8.OCNIdleState_3=TIM_OCNIDLESTATE_RESET
TIM8.OCNPolarity_1=TIM_OCNPOLARITY_HIGH
TIM8.OCNPolarity_2=TIM_OCNPOLARITY_HIGH
TIM8.OCNPolarity_3=TIM_OCNPOLARITY_HIGH
TIM8.OCPolarity_1=TIM_OCPOLARITY_HIGH
TIM8.OCPolarity_2=TIM_OCPOLARITY_HIGH
TIM8.OCPolarity_3=TIM_OCPOLARITY_HIGH
TIM8.OCPolarity_4=TIM_OCPOLARITY_HIGH
TIM8.OCPolarity_5=TIM_OCPOLARITY_HIGH
TIM8.OCPolarity_6=TIM_OCPOLARITY_HIGH
TIM8.OffStateIDLEMode=TIM_OSSI_ENABLE
TIM8.OffStateRunMode=TIM_OSSR_ENABLE
TIM8.Period=((PWM_PERIOD_CYCLES) / 2)
TIM8.Prescaler=((TIM_CLOCK_DIVIDER) - 1)
TIM8.Pulse-PWM\ Generation1\ CH1=((PWM_PERIOD_CYCLES) / 4)
TIM8.Pulse-PWM\ Generation2\ CH2=((PWM_PERIOD_CYCLES) / 4)
TIM8.Pulse-PWM\ Generation3\ CH3=((PWM_PERIOD_CYCLES) / 4)
TIM8.Pulse-PWM\ Generation4\ No\ Output=(((PWM_PERIOD_CYCLES) / 2) - (HTMIN))
TIM8.Pulse-PWM\ Generation5\ No\ Output=(((PWM_PERIOD_CYCLES) / 2) + 1)
TIM8.Pulse-PWM\ Generation6\ No\ Output=(((PWM_PERIOD_CYCLES) / 2) + 1)
TIM8.RepetitionCounter=(REP_COUNTER)
TIM8.TIM_MasterOutputTrigger=TIM_TRGO_OC4REF
TIM8.TIM_MasterOutputTrigger2=TIM_TRGO2_RESET
TIM8.TIM_MasterSlaveMode=TIM_MASTERSLAVEMODE_DISABLE
TIM8.TIM_SlaveMode=TIM_SLAVEMODE_TRIGGER
USART1.BaudRate=115200
USART1.VirtualMode-Asynchronous=VM_ASYNC
USART1.WordLength=WORDLENGTH_8B
VP_MotorControl_MC_ENABLED.Mode=Enabled
VP_TIM1_VS_ClockSourceITR.Mode=TriggerSource_ITR1
VP_TIM1_VS_ControllerModeTrigger.Mode=Trigger Mode
VP_TIM1_VS_no_output4.Mode=PWM Generation4 No Output
VP_TIM8_VS_ClockSourceITR.Mode=TriggerSource_ITR1
VP_TIM8_VS_ControllerModeTrigger.Mode=Trigger Mode
VP_TIM8_VS_no_output4.Mode=PWM Generation4 No Output
board=DualDriveCCMRAM

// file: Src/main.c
/**
  ******************************************************************************
  * @file           : main.c
  * @brief          : Main program body
  ******************************************************************************
  * @attention
  *
  * <h2><center>&copy; Copyright (c) 2019 STMicroelectronics.
  * All rights reserved.</center></h2>
  *
  * This software component is licensed by ST under Ultimate Liberty license
  * SLA0044, the "License"; You may not use this file except in compliance with
  * the License. You may obtain a copy of the License at:
  *                             www.st.com/SLA0044
  *
  ******************************************************************************
  */
#include "main.h"
#include "stm32f3xx_hal.h"
#include "motorcontrol.h"

/* USER CODE BEGIN Includes */
#include "speed_ramp_for_dual_drive.h"
/* USER CODE END Includes */

ADC_HandleTypeDef hadc1;
ADC_HandleTypeDef hadc2;
ADC_HandleTypeDef hadc3;
ADC_HandleTypeDef hadc4;

COMP_HandleTypeDef hcomp1;
COMP_HandleTypeDef hcomp2;
COMP_HandleTypeDef hcomp3;
COMP_HandleTypeDef hcomp4;
COMP_HandleTypeDef hcomp5;
COMP_HandleTypeDef hcomp6;

DAC_HandleTypeDef hdac1;

OPAMP_HandleTypeDef hopamp1;
OPAMP_HandleTypeDef hopamp2;
OPAMP_HandleTypeDef hopamp3;
OPAMP_HandleTypeDef hopamp4;

TIM_HandleTypeDef htim1;
TIM_HandleTypeDef htim8;

UART_HandleTypeDef huart1;

/* USER CODE BEGIN PV */
/* Private variables ---------------------------------------------------------*/

/* USER CODE END PV */

void SystemClock_Config(void);
static void MX_GPIO_Init(void);
static void MX_ADC1_Init(void);
static void MX_ADC2_Init(void);
static void MX_ADC3_Init(void);
static void MX_ADC4_Init(void);
static void MX_COMP1_Init(void);
static void MX_COMP2_Init(void);
static void MX_COMP3_Init(void);
static void MX_COMP4_Init(void);
static void MX_COMP5_Init(void);
static void MX_COMP6_Init(void);
static void MX_DAC1_Init(void);
static void MX_OPAMP1_Init(void);
static void MX_OPAMP2_Init(void);
static void MX_OPAMP3_Init(void);
static void MX_OPAMP4_Init(void);
static void MX_TIM1_Init(void);
static void MX_TIM8_Init(void);
static void MX_USART1_UART_Init(void);
static void MX_NVIC_Init(void);

void HAL_TIM_MspPostInit(TIM_HandleTypeDef *htim);

/* USER CODE BEGIN PFP */
/* Private function prototypes -----------------------------------------------*/

/* USER CODE END PFP */

int main(void)
{

  /* MCU Configuration----------------------------------------------------------*/

  /* Reset of all peripherals, Initializes the Flash interface and the Systick. */
  HAL_Init();

  /* Configure the system clock */
  SystemClock_Config();

  /* Initialize all configured peripherals */
  MX_GPIO_Init();
  MX_ADC1_Init();
  MX_ADC2_Init();
  MX_ADC3_Init();
  MX_ADC4_Init();
  MX_COMP1_Init();
  MX_COMP2_Init();
  MX_COMP3_Init();
  MX_COMP4_Init();
  MX_COMP5_Init();
  MX_COMP6_Init();
  MX_DAC1_Init();
  MX_OPAMP1_Init();
  MX_OPAMP2_Init();
  MX_OPAMP3_Init();
  MX_OPAMP4_Init();
  MX_TIM1_Init();
  MX_TIM8_Init();
  MX_USART1_UART_Init();
  MX_MotorControl_Init();

  /* Initialize interrupts */
  MX_NVIC_Init();

  /* Infinite loop */
  /* USER CODE BEGIN WHILE */
  while (1)
  {
    demo_dual_drive();
  /* USER CODE END WHILE */

  }

}

void SystemClock_Config(void)
{

  RCC_OscInitTypeDef RCC_OscInitStruct;
  RCC_ClkInitTypeDef RCC_ClkInitStruct;
  RCC_PeriphCLKInitTypeDef PeriphClkInit;

    /**Initializes the CPU, AHB and APB busses clocks
    */
  RCC_OscInitStruct.OscillatorType = RCC_OSCILLATORTYPE_HSE;
  RCC_OscInitStruct.HSEState = RCC_HSE_ON;
  RCC_OscInitStruct.HSIState = RCC_HSI_ON;
  RCC_OscInitStruct.PLL.PLLState = RCC_PLL_ON;
  RCC_OscInitStruct.PLL.PLLSource = RCC_PLLSOURCE_HSE;
  RCC_OscInitStruct.PLL.PLLMUL = RCC_PLL_MUL9;
  RCC_OscInitStruct.PLL.PREDIV = RCC_PREDIV_DIV1;
  if (HAL_RCC_OscConfig(&RCC_OscInitStruct) != HAL_OK)
  {
    _Error_Handler(__FILE__, __LINE__);
  }

    /**Initializes the CPU, AHB and APB busses clocks
    */
  RCC_ClkInitStruct.ClockType = RCC_CLOCKTYPE_HCLK|RCC_CLOCKTYPE_SYSCLK
                              |RCC_CLOCKTYPE_PCLK1|RCC_CLOCKTYPE_PCLK2;
  RCC_ClkInitStruct.SYSCLKSource = RCC_SYSCLKSOURCE_PLLCLK;
  RCC_ClkInitStruct.AHBCLKDivider = RCC_SYSCLK_DIV1;
  RCC_ClkInitStruct.APB1CLKDivider = RCC_HCLK_DIV2;
  RCC_ClkInitStruct.APB2CLKDivider = RCC_HCLK_DIV1;

  if (HAL_RCC_ClockConfig(&RCC_ClkInitStruct, FLASH_LATENCY_2) != HAL_OK)
  {
    _Error_Handler(__FILE__, __LINE__);
  }

  PeriphClkInit.PeriphClockSelection = RCC_PERIPHCLK_USART1|RCC_PERIPHCLK_TIM1
                              |RCC_PERIPHCLK_TIM8;
  PeriphClkInit.Usart1ClockSelection = RCC_USART1CLKSOURCE_PCLK2;
  PeriphClkInit.Tim1ClockSelection = RCC_TIM1CLK_HCLK;
  PeriphClkInit.Tim8ClockSelection = RCC_TIM8CLK_HCLK;
  if (HAL_RCCEx_PeriphCLKConfig(&PeriphClkInit) != HAL_OK)
  {
    _Error_Handler(__FILE__, __LINE__);
  }

    /**Enables the Clock Security System
    */
  HAL_RCC_EnableCSS();

    /**Configure the Systick interrupt time
    */
  HAL_SYSTICK_Config(HAL_RCC_GetHCLKFreq()/1000);

    /**Configure the Systick
    */
  HAL_SYSTICK_CLKSourceConfig(SYSTICK_CLKSOURCE_HCLK);

  /* SysTick_IRQn interrupt configuration */
  HAL_NVIC_SetPriority(SysTick_IRQn, 4, 0);
}

/**
  * @brief NVIC Configuration.
  * @retval None
  */
static void MX_NVIC_Init(void)
{
  /* TIM1_BRK_TIM15_IRQn interrupt configuration */
  HAL_NVIC_SetPriority(TIM1_BRK_TIM15_IRQn, 4, 1);
  HAL_NVIC_EnableIRQ(TIM1_BRK_TIM15_IRQn);
  /* ADC1_2_IRQn interrupt configuration */
  HAL_NVIC_SetPriority(ADC1_2_IRQn, 2, 0);
  HAL_NVIC_EnableIRQ(ADC1_2_IRQn);
  /* TIM8_BRK_IRQn interrupt configuration */
  HAL_NVIC_SetPriority(TIM8_BRK_IRQn, 4, 1);
  HAL_NVIC_EnableIRQ(TIM8_BRK_IRQn);
  /* ADC3_IRQn interrupt configuration */
  HAL_NVIC_SetPriority(ADC3_IRQn, 2, 0);
  HAL_NVIC_EnableIRQ(ADC3_IRQn);
  /* USART1_IRQn interrupt configuration */
  HAL_NVIC_SetPriority(USART1_IRQn, 3, 1);
  HAL_NVIC_EnableIRQ(USART1_IRQn);
  /* EXTI9_5_IRQn interrupt configuration */
  HAL_NVIC_SetPriority(EXTI9_5_IRQn, 0, 0);
  HAL_NVIC_EnableIRQ(EXTI9_5_IRQn);
}

/* ADC1 init function */
static void MX_ADC1_Init(void)
{

  ADC_MultiModeTypeDef multimode;
  ADC_InjectionConfTypeDef sConfigInjected;
  ADC_ChannelConfTypeDef sConfig;

    /**Common config
    */
  hadc1.Instance = ADC1;
  hadc1.Init.ClockPrescaler = ADC_CLOCK_SYNC_PCLK_DIV4;
  hadc1.Init.Resolution = ADC_RESOLUTION_12B;
  hadc1.Init.ScanConvMode = ADC_SCAN_ENABLE;
  hadc1.Init.ContinuousConvMode = DISABLE;
  hadc1.Init.DiscontinuousConvMode = DISABLE;
  hadc1.Init.ExternalTrigConvEdge = ADC_EXTERNALTRIGCONVEDGE_NONE;
  hadc1.Init.ExternalTrigConv = ADC_SOFTWARE_START;
  hadc1.Init.DataAlign = ADC_DATAALIGN_LEFT;
  hadc1.Init.NbrOfConversion = 3;
  hadc1.Init.DMAContinuousRequests = DISABLE;
  hadc1.Init.EOCSelection = ADC_EOC_SINGLE_CONV;
  hadc1.Init.LowPowerAutoWait = DISABLE;
  hadc1.Init.Overrun = ADC_OVR_DATA_PRESERVED;
  if (HAL_ADC_Init(&hadc1) != HAL_OK)
  {
    _Error_Handler(__FILE__, __LINE__);
  }

    /**Configure the ADC multi-mode
    */
  multimode.Mode = ADC_MODE_INDEPENDENT;
  if (HAL_ADCEx_MultiModeConfigChannel(&hadc1, &multimode) != HAL_OK)
  {
    _Error_Handler(__FILE__, __LINE__);
  }

    /**Configure Injected Channel
    */
  sConfigInjected.InjectedChannel = ADC_CHANNEL_3;
  sConfigInjected.InjectedRank = ADC_INJECTED_RANK_1;
  sConfigInjected.InjectedSingleDiff = ADC_SINGLE_ENDED;
  sConfigInjected.InjectedNbrOfConversion = 1;
  sConfigInjected.InjectedSamplingTime = ADC_SAMPLETIME_7CYCLES_5;
  sConfigInjected.ExternalTrigInjecConvEdge = ADC_EXTERNALTRIGINJECCONV_EDGE_RISING;
  sConfigInjected.ExternalTrigInjecConv = ADC_EXTERNALTRIGINJECCONV_T1_TRGO;
  sConfigInjected.AutoInjectedConv = DISABLE;
  sConfigInjected.InjectedDiscontinuousConvMode = DISABLE;
  sConfigInjected.QueueInjectedContext = ENABLE;
  sConfigInjected.InjectedOffset = 0;
  sConfigInjected.InjectedOffsetNumber = ADC_OFFSET_NONE;
  if (HAL_ADCEx_InjectedConfigChannel(&hadc1, &sConfigInjected) != HAL_OK)
  {
    _Error_Handler(__FILE__, __LINE__);
  }

    /**Configure Regular Channel
    */
  sConfig.Channel = ADC_CHANNEL_1;
  sConfig.Rank = ADC_REGULAR_RANK_1;
  sConfig.SingleDiff = ADC_SINGLE_ENDED;
  sConfig.SamplingTime = ADC_SAMPLETIME_61CYCLES_5;
  sConfig.OffsetNumber = ADC_OFFSET_NONE;
  sConfig.Offset = 0;
  if (HAL_ADC_ConfigChannel(&hadc1, &sConfig) != HAL_OK)
  {
    _Error_Handler(__FILE__, __LINE__);
  }

    /**Configure Regular Channel
    */
  sConfig.Channel = ADC_CHANNEL_7;
  sConfig.Rank = ADC_REGULAR_RANK_2;
  if (HAL_ADC_ConfigChannel(&hadc1, &sConfig) != HAL_OK)
  {
    _Error_Handler(__FILE__, __LINE__);
  }

    /**Configure Regular Channel
    */
  sConfig.Channel = ADC_CHANNEL_10;
  sConfig.Rank = ADC_REGULAR_RANK_3;
  if (HAL_ADC_ConfigChannel(&hadc1, &sConfig) != HAL_OK)
  {
    _Error_Handler(__FILE__, __LINE__);
  }

}

/* ADC2 init function */
static void MX_ADC2_Init(void)
{

  ADC_InjectionConfTypeDef sConfigInjected;

    /**Common config
    */
  hadc2.Instance = ADC2;
  hadc2.Init.ClockPrescaler = ADC_CLOCK_SYNC_PCLK_DIV4;
  hadc2.Init.Resolution = ADC_RESOLUTION_12B;
  hadc2.Init.ScanConvMode = ADC_SCAN_DISABLE;
  hadc2.Init.ContinuousConvMode = DISABLE;
  hadc2.Init.DiscontinuousConvMode = DISABLE;
  hadc2.Init.DataAlign = ADC_DATAALIGN_LEFT;
  hadc2.Init.NbrOfConversion = 1;
  hadc2.Init.DMAContinuousRequests = DISABLE;
  hadc2.Init.EOCSelection = ADC_EOC_SINGLE_CONV;
  hadc2.Init.LowPowerAutoWait = DISABLE;
  hadc2.Init.Overrun = ADC_OVR_DATA_PRESERVED;
  if (HAL_ADC_Init(&hadc2) != HAL_OK)
  {
    _Error_Handler(__FILE__, __LINE__);
  }

    /**Configure Injected Channel
    */
  sConfigInjected.InjectedChannel = ADC_CHANNEL_3;
  sConfigInjected.InjectedRank = ADC_INJECTED_RANK_1;
  sConfigInjected.InjectedSingleDiff = ADC_SINGLE_ENDED;
  sConfigInjected.InjectedNbrOfConversion = 1;
  sConfigInjected.InjectedSamplingTime = ADC_SAMPLETIME_7CYCLES_5;
  sConfigInjected.ExternalTrigInjecConvEdge = ADC_EXTERNALTRIGINJECCONV_EDGE_RISING;
  sConfigInjected.ExternalTrigInjecConv = ADC_EXTERNALTRIGINJECCONV_T1_TRGO;
  sConfigInjected.AutoInjectedConv = DISABLE;
  sConfigInjected.InjectedDiscontinuousConvMode = DISABLE;
  sConfigInjected.QueueInjectedContext = ENABLE;
  sConfigInjected.InjectedOffset = 0;
  sConfigInjected.InjectedOffsetNumber = ADC_OFFSET_NONE;
  if (HAL_ADCEx_InjectedConfigChannel(&hadc2, &sConfigInjected) != HAL_OK)
  {
    _Error_Handler(__FILE__, __LINE__);
  }

}

/* ADC3 init function */
static void MX_ADC3_Init(void)
{

  ADC_MultiModeTypeDef multimode;
  ADC_InjectionConfTypeDef sConfigInjected;

    /**Common config
    */
  hadc3.Instance = ADC3;
  hadc3.Init.ClockPrescaler = ADC_CLOCK_SYNC_PCLK_DIV4;
  hadc3.Init.Resolution = ADC_RESOLUTION_12B;
  hadc3.Init.ScanConvMode = ADC_SCAN_DISABLE;
  hadc3.Init.ContinuousConvMode = DISABLE;
  hadc3.Init.DiscontinuousConvMode = DISABLE;
  hadc3.Init.DataAlign = ADC_DATAALIGN_LEFT;
  hadc3.Init.NbrOfConversion = 1;
  hadc3.Init.DMAContinuousRequests = DISABLE;
  hadc3.Init.EOCSelection = ADC_EOC_SINGLE_CONV;
  hadc3.Init.LowPowerAutoWait = DISABLE;
  hadc3.Init.Overrun = ADC_OVR_DATA_PRESERVED;
  if (HAL_ADC_Init(&hadc3) != HAL_OK)
  {
    _Error_Handler(__FILE__, __LINE__);
  }

    /**Configure the ADC multi-mode
    */
  multimode.Mode = ADC_MODE_INDEPENDENT;
  if (HAL_ADCEx_MultiModeConfigChannel(&hadc3, &multimode) != HAL_OK)
  {
    _Error_Handler(__FILE__, __LINE__);
  }

    /**Configure Injected Channel
    */
  sConfigInjected.InjectedChannel = ADC_CHANNEL_1;
  sConfigInjected.InjectedRank = ADC_INJECTED_RANK_1;
  sConfigInjected.InjectedSingleDiff = ADC_SINGLE_ENDED;
  sConfigInjected.InjectedNbrOfConversion = 1;
  sConfigInjected.InjectedSamplingTime = ADC_SAMPLETIME_7CYCLES_5;
  sConfigInjected.ExternalTrigInjecConvEdge = ADC_EXTERNALTRIGINJECCONV_EDGE_RISING;
  sConfigInjected.ExternalTrigInjecConv = ADC_EXTERNALTRIGINJECCONV_T8_TRGO;
  sConfigInjected.AutoInjectedConv = DISABLE;
  sConfigInjected.InjectedDiscontinuousConvMode = DISABLE;
  sConfigInjected.QueueInjectedContext = ENABLE;
  sConfigInjected.InjectedOffset = 0;
  sConfigInjected.InjectedOffsetNumber = ADC_OFFSET_NONE;
  if (HAL_ADCEx_InjectedConfigChannel(&hadc3, &sConfigInjected) != HAL_OK)
  {
    _Error_Handler(__FILE__, __LINE__);
  }

}

/* ADC4 init function */
static void MX_ADC4_Init(void)
{

  ADC_InjectionConfTypeDef sConfigInjected;

    /**Common config
    */
  hadc4.Instance = ADC4;
  hadc4.Init.ClockPrescaler = ADC_CLOCK_SYNC_PCLK_DIV4;
  hadc4.Init.Resolution = ADC_RESOLUTION_12B;
  hadc4.Init.ScanConvMode = ADC_SCAN_DISABLE;
  hadc4.Init.ContinuousConvMode = DISABLE;
  hadc4.Init.DiscontinuousConvMode = DISABLE;
  hadc4.Init.DataAlign = ADC_DATAALIGN_LEFT;
  hadc4.Init.NbrOfConversion = 1;
  hadc4.Init.DMAContinuousRequests = DISABLE;
  hadc4.Init.EOCSelection = ADC_EOC_SINGLE_CONV;
  hadc4.Init.LowPowerAutoWait = DISABLE;
  hadc4.Init.Overrun = ADC_OVR_DATA_PRESERVED;
  if (HAL_ADC_Init(&hadc4) != HAL_OK)
  {
    _Error_Handler(__FILE__, __LINE__);
  }

    /**Configure Injected Channel
    */
  sConfigInjected.InjectedChannel = ADC_CHANNEL_3;
  sConfigInjected.InjectedRank = ADC_INJECTED_RANK_1;
  sConfigInjected.InjectedSingleDiff = ADC_SINGLE_ENDED;
  sConfigInjected.InjectedNbrOfConversion = 1;
  sConfigInjected.InjectedSamplingTime = ADC_SAMPLETIME_7CYCLES_5;
  sConfigInjected.ExternalTrigInjecConvEdge = ADC_EXTERNALTRIGINJECCONV_EDGE_RISING;
  sConfigInjected.ExternalTrigInjecConv = ADC_EXTERNALTRIGINJECCONV_T8_TRGO;
  sConfigInjected.AutoInjectedConv = DISABLE;
  sConfigInjected.InjectedDiscontinuousConvMode = DISABLE;
  sConfigInjected.QueueInjectedContext = ENABLE;
  sConfigInjected.InjectedOffset = 0;
  sConfigInjected.InjectedOffsetNumber = ADC_OFFSET_NONE;
  if (HAL_ADCEx_InjectedConfigChannel(&hadc4, &sConfigInjected) != HAL_OK)
  {
    _Error_Handler(__FILE__, __LINE__);
  }

}

/* COMP1 init function */
static void MX_COMP1_Init(void)
{

  hcomp1.Instance = COMP1;
  hcomp1.Init.InvertingInput = COMP_INVERTINGINPUT_DAC1_CH1;
  hcomp1.Init.NonInvertingInput = COMP_NONINVERTINGINPUT_IO1;
  hcomp1.Init.Output = COMP_OUTPUT_TIM1BKIN2;
  hcomp1.Init.OutputPol = COMP_OUTPUTPOL_NONINVERTED;
  hcomp1.Init.BlankingSrce = COMP_BLANKINGSRCE_NONE;
  hcomp1.Init.TriggerMode = COMP_TRIGGERMODE_NONE;
  if (HAL_COMP_Init(&hcomp1) != HAL_OK)
  {
    _Error_Handler(__FILE__, __LINE__);
  }

}

/* COMP2 init function */
static void MX_COMP2_Init(void)
{

  hcomp2.Instance = COMP2;
  hcomp2.Init.InvertingInput = COMP_INVERTINGINPUT_DAC1_CH1;
  hcomp2.Init.NonInvertingInput = COMP_NONINVERTINGINPUT_IO1;
  hcomp2.Init.Output = COMP_OUTPUT_TIM1BKIN2;
  hcomp2.Init.OutputPol = COMP_OUTPUTPOL_NONINVERTED;
  hcomp2.Init.BlankingSrce = COMP_BLANKINGSRCE_NONE;
  hcomp2.Init.TriggerMode = COMP_TRIGGERMODE_NONE;
  if (HAL_COMP_Init(&hcomp2) != HAL_OK)
  {
    _Error_Handler(__FILE__, __LINE__);
  }

}

/* COMP3 init function */
static void MX_COMP3_Init(void)
{

  hcomp3.Instance = COMP3;
  hcomp3.Init.InvertingInput = COMP_INVERTINGINPUT_DAC1_CH1;
  hcomp3.Init.NonInvertingInput = COMP_NONINVERTINGINPUT_IO1;
  hcomp3.Init.Output = COMP_OUTPUT_TIM1BKIN2;
  hcomp3.Init.OutputPol = COMP_OUTPUTPOL_NONINVERTED;
  hcomp3.Init.BlankingSrce = COMP_BLANKINGSRCE_NONE;
  hcomp3.Init.TriggerMode = COMP_TRIGGERMODE_NONE;
  if (HAL_COMP_Init(&hcomp3) != HAL_OK)
  {
    _Error_Handler(__FILE__, __LINE__);
  }

}

/* COMP4 init function */
static void MX_COMP4_Init(void)
{

  hcomp4.Instance = COMP4;
  hcomp4.Init.InvertingInput = COMP_INVERTINGINPUT_DAC1_CH1;
  hcomp4.Init.NonInvertingInput = COMP_NONINVERTINGINPUT_IO1;
  hcomp4.Init.Output = COMP_OUTPUT_TIM8BKIN2;
  hcomp4.Init.OutputPol = COMP_OUTPUTPOL_NONINVERTED;
  hcomp4.Init.BlankingSrce = COMP_BLANKINGSRCE_NONE;
  hcomp4.Init.TriggerMode = COMP_TRIGGERMODE_NONE;
  if (HAL_COMP_Init(&hcomp4) != HAL_OK)
  {
    _Error_Handler(__FILE__, __LINE__);
  }

}

/* COMP5 init function */
static void MX_COMP5_Init(void)
{

  hcomp5.Instance = COMP5;
  hcomp5.Init.InvertingInput = COMP_INVERTINGINPUT_DAC1_CH1;
  hcomp5.Init.NonInvertingInput = COMP_NONINVERTINGINPUT_IO1;
  hcomp5.Init.Output = COMP_OUTPUT_TIM8BKIN2;
  hcomp5.Init.OutputPol = COMP_OUTPUTPOL_NONINVERTED;
  hcomp5.Init.BlankingSrce = COMP_BLANKINGSRCE_NONE;
  hcomp5.Init.TriggerMode = COMP_TRIGGERMODE_NONE;
  if (HAL_COMP_Init(&hcomp5) != HAL_OK)
  {
    _Error_Handler(__FILE__, __LINE__);
  }

}

/* COMP6 init function */
static void MX_COMP6_Init(void)
{

  hcomp6.Instance = COMP6;
  hcomp6.Init.InvertingInput = COMP_INVERTINGINPUT_DAC1_CH1;
  hcomp6.Init.NonInvertingInput = COMP_NONINVERTINGINPUT_IO1;
  hcomp6.Init.Output = COMP_OUTPUT_TIM8BKIN2;
  hcomp6.Init.OutputPol = COMP_OUTPUTPOL_NONINVERTED;
  hcomp6.Init.BlankingSrce = COMP_BLANKINGSRCE_NONE;
  hcomp6.Init.TriggerMode = COMP_TRIGGERMODE_NONE;
  if (HAL_COMP_Init(&hcomp6) != HAL_OK)
  {
    _Error_Handler(__FILE__, __LINE__);
  }

}

/* DAC1 init function */
static void MX_DAC1_Init(void)
{

  DAC_ChannelConfTypeDef sConfig;

    /**DAC Initialization
    */
  hdac1.Instance = DAC1;
  if (HAL_DAC_Init(&hdac1) != HAL_OK)
  {
    _Error_Handler(__FILE__, __LINE__);
  }

    /**DAC channel OUT1 config
    */
  sConfig.DAC_Trigger = DAC_TRIGGER_SOFTWARE;
  sConfig.DAC_OutputBuffer = DAC_OUTPUTBUFFER_DISABLE;
  if (HAL_DAC_ConfigChannel(&hdac1, &sConfig, DAC_CHANNEL_1) != HAL_OK)
  {
    _Error_Handler(__FILE__, __LINE__);
  }

    /**DAC channel OUT2 config
    */
  if (HAL_DAC_ConfigChannel(&hdac1, &sConfig, DAC_CHANNEL_2) != HAL_OK)
  {
    _Error_Handler(__FILE__, __LINE__);
  }

}

/* OPAMP1 init function */
static void MX_OPAMP1_Init(void)
{

  hopamp1.Instance = OPAMP1;
  hopamp1.Init.Mode = OPAMP_PGA_MODE;
  hopamp1.Init.NonInvertingInput = OPAMP_NONINVERTINGINPUT_IO0;
  hopamp1.Init.TimerControlledMuxmode = OPAMP_TIMERCONTROLLEDMUXMODE_DISABLE;
  hopamp1.Init.PgaConnect = OPAMP_PGA_CONNECT_INVERTINGINPUT_NO;
  hopamp1.Init.PgaGain = OPAMP_PGA_GAIN_2;
  hopamp1.Init.UserTrimming = OPAMP_TRIMMING_FACTORY;
  if (HAL_OPAMP_Init(&hopamp1) != HAL_OK)
  {
    _Error_Handler(__FILE__, __LINE__);
  }

}

/* OPAMP2 init function */
static void MX_OPAMP2_Init(void)
{

  hopamp2.Instance = OPAMP2;
  hopamp2.Init.Mode = OPAMP_PGA_MODE;
  hopamp2.Init.NonInvertingInput = OPAMP_NONINVERTINGINPUT_IO0;
  hopamp2.Init.TimerControlledMuxmode = OPAMP_TIMERCONTROLLEDMUXMODE_DISABLE;
  hopamp2.Init.PgaConnect = OPAMP_PGA_CONNECT_INVERTINGINPUT_NO;
  hopamp2.Init.PgaGain = OPAMP_PGA_GAIN_2;
  hopamp2.Init.UserTrimming = OPAMP_TRIMMING_FACTORY;
  if (HAL_OPAMP_Init(&hopamp2) != HAL_OK)
  {
    _Error_Handler(__FILE__, __LINE__);
  }

}

/* OPAMP3 init function */
static void MX_OPAMP3_Init(void)
{

  hopamp3.Instance = OPAMP3;
  hopamp3.Init.Mode = OPAMP_PGA_MODE;
  hopamp3.Init.NonInvertingInput = OPAMP_NONINVERTINGINPUT_IO0;
  hopamp3.Init.TimerControlledMuxmode = OPAMP_TIMERCONTROLLEDMUXMODE_DISABLE;
  hopamp3.Init.PgaConnect = OPAMP_PGA_CONNECT_INVERTINGINPUT_NO;
  hopamp3.Init.PgaGain = OPAMP_PGA_GAIN_2;
  hopamp3.Init.UserTrimming = OPAMP_TRIMMING_FACTORY;
  if (HAL_OPAMP_Init(&hopamp3) != HAL_OK)
  {
    _Error_Handler(__FILE__, __LINE__);
  }

}

/* OPAMP4 init function */
static void MX_OPAMP4_Init(void)
{

  hopamp4.Instance = OPAMP4;
  hopamp4.Init.Mode = OPAMP_PGA_MODE;
  hopamp4.Init.NonInvertingInput = OPAMP_NONINVERTINGINPUT_IO0;
  hopamp4.Init.TimerControlledMuxmode = OPAMP_TIMERCONTROLLEDMUXMODE_DISABLE;
  hopamp4.Init.PgaConnect = OPAMP_PGA_CONNECT_INVERTINGINPUT_NO;
  hopamp4.Init.PgaGain = OPAMP_PGA_GAIN_2;
  hopamp4.Init.UserTrimming = OPAMP_TRIMMING_FACTORY;
  if (HAL_OPAMP_Init(&hopamp4) != HAL_OK)
  {
    _Error_Handler(__FILE__, __LINE__);
  }

}

/* TIM1 init function */
static void MX_TIM1_Init(void)
{

  TIM_SlaveConfigTypeDef sSlaveConfig;
  TIM_MasterConfigTypeDef sMasterConfig;
  TIM_OC_InitTypeDef sConfigOC;
  TIM_BreakDeadTimeConfigTypeDef sBreakDeadTimeConfig;

  htim1.Instance = TIM1;
  htim1.Init.Prescaler = ((TIM_CLOCK_DIVIDER) - 1);
  htim1.Init.CounterMode = TIM_COUNTERMODE_CENTERALIGNED1;
  htim1.Init.Period = ((PWM_PERIOD_CYCLES) / 2);
  htim1.Init.ClockDivision = TIM_CLOCKDIVISION_DIV2;
  htim1.Init.RepetitionCounter = (REP_COUNTER);
  htim1.Init.AutoReloadPreload = TIM_AUTORELOAD_PRELOAD_DISABLE;
  if (HAL_TIM_Base_Init(&htim1) != HAL_OK)
  {
    _Error_Handler(__FILE__, __LINE__);
  }

  if (HAL_TIM_PWM_Init(&htim1) != HAL_OK)
  {
    _Error_Handler(__FILE__, __LINE__);
  }

  sSlaveConfig.SlaveMode = TIM_SLAVEMODE_TRIGGER;
  sSlaveConfig.InputTrigger = TIM_TS_ITR1;
  if (HAL_TIM_SlaveConfigSynchronization(&htim1, &sSlaveConfig) != HAL_OK)
  {
    _Error_Handler(__FILE__, __LINE__);
  }

  sMasterConfig.MasterOutputTrigger = TIM_TRGO_OC4REF;
  sMasterConfig.MasterOutputTrigger2 = TIM_TRGO2_RESET;
  sMasterConfig.MasterSlaveMode = TIM_MASTERSLAVEMODE_DISABLE;
  if (HAL_TIMEx_MasterConfigSynchronization(&htim1, &sMasterConfig) != HAL_OK)
  {
    _Error_Handler(__FILE__, __LINE__);
  }

  sConfigOC.OCMode = TIM_OCMODE_PWM1;
  sConfigOC.Pulse = 0;
  sConfigOC.OCPolarity = TIM_OCPOLARITY_HIGH;
  sConfigOC.OCNPolarity = TIM_OCNPOLARITY_HIGH;
  sConfigOC.OCFastMode = TIM_OCFAST_DISABLE;
  sConfigOC.OCIdleState = TIM_OCIDLESTATE_RESET;
  sConfigOC.OCNIdleState = TIM_OCNIDLESTATE_RESET;
  if (HAL_TIM_PWM_ConfigChannel(&htim1, &sConfigOC, TIM_CHANNEL_1) != HAL_OK)
  {
    _Error_Handler(__FILE__, __LINE__);
  }

  if (HAL_TIM_PWM_ConfigChannel(&htim1, &sConfigOC, TIM_CHANNEL_2) != HAL_OK)
  {
    _Error_Handler(__FILE__, __LINE__);
  }

  if (HAL_TIM_PWM_ConfigChannel(&htim1, &sConfigOC, TIM_CHANNEL_3) != HAL_OK)
  {
    _Error_Handler(__FILE__, __LINE__);
  }

  sConfigOC.OCMode = TIM_OCMODE_PWM2;
  sConfigOC.Pulse = (((PWM_PERIOD_CYCLES) / 2) - (HTMIN));
  if (HAL_TIM_PWM_ConfigChannel(&htim1, &sConfigOC, TIM_CHANNEL_4) != HAL_OK)
  {
    _Error_Handler(__FILE__, __LINE__);
  }

  sBreakDeadTimeConfig.OffStateRunMode = TIM_OSSR_ENABLE;
  sBreakDeadTimeConfig.OffStateIDLEMode = TIM_OSSI_ENABLE;
  sBreakDeadTimeConfig.LockLevel = TIM_LOCKLEVEL_1;
  sBreakDeadTimeConfig.DeadTime = ((DEAD_TIME_COUNTS) / 2);
  sBreakDeadTimeConfig.BreakState = TIM_BREAK_ENABLE;
  sBreakDeadTimeConfig.BreakPolarity = TIM_BREAKPOLARITY_HIGH;
  sBreakDeadTimeConfig.BreakFilter = 0;
  sBreakDeadTimeConfig.Break2State = TIM_BREAK2_ENABLE;
  sBreakDeadTimeConfig.Break2Polarity = TIM_BREAK2POLARITY_HIGH;
  sBreakDeadTimeConfig.Break2Filter = 4;
  sBreakDeadTimeConfig.AutomaticOutput = TIM_AUTOMATICOUTPUT_DISABLE;
  if (HAL_TIMEx_ConfigBreakDeadTime(&htim1, &sBreakDeadTimeConfig) != HAL_OK)
  {
    _Error_Handler(__FILE__, __LINE__);
  }

  HAL_TIM_MspPostInit(&htim1);

}

/* TIM8 init function */
static void MX_TIM8_Init(void)
{

  TIM_SlaveConfigTypeDef sSlaveConfig;
  TIM_MasterConfigTypeDef sMasterConfig;
  TIM_OC_InitTypeDef sConfigOC;
  TIM_BreakDeadTimeConfigTypeDef sBreakDeadTimeConfig;

  htim8.Instance = TIM8;
  htim8.Init.Prescaler = ((TIM_CLOCK_DIVIDER) - 1);
  htim8.Init.CounterMode = TIM_COUNTERMODE_CENTERALIGNED1;
  htim8.Init.Period = ((PWM_PERIOD_CYCLES) / 2);
  htim8.Init.ClockDivision = TIM_CLOCKDIVISION_DIV2;
  htim8.Init.RepetitionCounter = (REP_COUNTER);
  htim8.Init.AutoReloadPreload = TIM_AUTORELOAD_PRELOAD_DISABLE;
  if (HAL_TIM_Base_Init(&htim8) != HAL_OK)
  {
    _Error_Handler(__FILE__, __LINE__);
  }

  if (HAL_TIM_PWM_Init(&htim8) != HAL_OK)
  {
    _Error_Handler(__FILE__, __LINE__);
  }

  sSlaveConfig.SlaveMode = TIM_SLAVEMODE_TRIGGER;
  sSlaveConfig.InputTrigger = TIM_TS_ITR1;
  if (HAL_TIM_SlaveConfigSynchronization(&htim8, &sSlaveConfig) != HAL_OK)
  {
    _Error_Handler(__FILE__, __LINE__);
  }

  sMasterConfig.MasterOutputTrigger = TIM_TRGO_OC4REF;
  sMasterConfig.MasterOutputTrigger2 = TIM_TRGO2_RESET;
  sMasterConfig.MasterSlaveMode = TIM_MASTERSLAVEMODE_DISABLE;
  if (HAL_TIMEx_MasterConfigSynchronization(&htim8, &sMasterConfig) != HAL_OK)
  {
    _Error_Handler(__FILE__, __LINE__);
  }

  sConfigOC.OCMode = TIM_OCMODE_PWM1;
  sConfigOC.Pulse = 0;
  sConfigOC.OCPolarity = TIM_OCPOLARITY_HIGH;
  sConfigOC.OCNPolarity = TIM_OCNPOLARITY_HIGH;
  sConfigOC.OCFastMode = TIM_OCFAST_DISABLE;
  sConfigOC.OCIdleState = TIM_OCIDLESTATE_RESET;
  sConfigOC.OCNIdleState = TIM_OCNIDLESTATE_RESET;
  if (HAL_TIM_PWM_ConfigChannel(&htim8, &sConfigOC, TIM_CHANNEL_1) != HAL_OK)
  {
    _Error_Handler(__FILE__, __LINE__);
  }

  if (HAL_TIM_PWM_ConfigChannel(&htim8, &sConfigOC, TIM_CHANNEL_2) != HAL_OK)
  {
    _Error_Handler(__FILE__, __LINE__);
  }

  if (HAL_TIM_PWM_ConfigChannel(&htim8, &sConfigOC, TIM_CHANNEL_3) != HAL_OK)
  {
    _Error_Handler(__FILE__, __LINE__);
  }

  sConfigOC.OCMode = TIM_OCMODE_PWM2;
  sConfigOC.Pulse = (((PWM_PERIOD_CYCLES) / 2) - (HTMIN));
  if (HAL_TIM_PWM_ConfigChannel(&htim8, &sConfigOC, TIM_CHANNEL_4) != HAL_OK)
  {
    _Error_Handler(__FILE__, __LINE__);
  }

  sBreakDeadTimeConfig.OffStateRunMode = TIM_OSSR_ENABLE;
  sBreakDeadTimeConfig.OffStateIDLEMode = TIM_OSSI_ENABLE;
  sBreakDeadTimeConfig.LockLevel = TIM_LOCKLEVEL_1;
  sBreakDeadTimeConfig.DeadTime = ((DEAD_TIME_COUNTS) / 2);
  sBreakDeadTimeConfig.BreakState = TIM_BREAK_ENABLE;
  sBreakDeadTimeConfig.BreakPolarity = TIM_BREAKPOLARITY_HIGH;
  sBreakDeadTimeConfig.BreakFilter = 0;
  sBreakDeadTimeConfig.Break2State = TIM_BREAK2_ENABLE;
  sBreakDeadTimeConfig.Break2Polarity = TIM_BREAK2POLARITY_HIGH;
  sBreakDeadTimeConfig.Break2Filter = 4;
  sBreakDeadTimeConfig.AutomaticOutput = TIM_AUTOMATICOUTPUT_DISABLE;
  if (HAL_TIMEx_ConfigBreakDeadTime(&htim8, &sBreakDeadTimeConfig) != HAL_OK)
  {
    _Error_Handler(__FILE__, __LINE__);
  }

  HAL_TIM_MspPostInit(&htim8);

}

/* USART1 init function */
static void MX_USART1_UART_Init(void)
{

  huart1.Instance = USART1;
  huart1.Init.BaudRate = 115200;
  huart1.Init.WordLength = UART_WORDLENGTH_8B;
  huart1.Init.StopBits = UART_STOPBITS_1;
  huart1.Init.Parity = UART_PARITY_NONE;
  huart1.Init.Mode = UART_MODE_TX_RX;
  huart1.Init.HwFlowCtl = UART_HWCONTROL_NONE;
  huart1.Init.OverSampling = UART_OVERSAMPLING_16;
  huart1.Init.OneBitSampling = UART_ONE_BIT_SAMPLE_DISABLE;
  huart1.AdvancedInit.AdvFeatureInit = UART_ADVFEATURE_NO_INIT;
  if (HAL_UART_Init(&huart1) != HAL_OK)
  {
    _Error_Handler(__FILE__, __LINE__);
  }

}

/** Configure pins as
        * Analog
        * Input
        * Output
        * EVENT_OUT
        * EXTI
*/
static void MX_GPIO_Init(void)
{

  GPIO_InitTypeDef GPIO_InitStruct;

  /* GPIO Ports Clock Enable */
  __HAL_RCC_GPIOE_CLK_ENABLE();
  __HAL_RCC_GPIOF_CLK_ENABLE();
  __HAL_RCC_GPIOC_CLK_ENABLE();
  __HAL_RCC_GPIOA_CLK_ENABLE();
  __HAL_RCC_GPIOB_CLK_ENABLE();

  /*Configure GPIO pin : Start_Stop_Pin */
  GPIO_InitStruct.Pin = Start_Stop_Pin;
  GPIO_InitStruct.Mode = GPIO_MODE_IT_FALLING;
  GPIO_InitStruct.Pull = GPIO_NOPULL;
  HAL_GPIO_Init(Start_Stop_GPIO_Port, &GPIO_InitStruct);

}

void _Error_Handler(char *file, int line)
{
  while(1)
  {
  }
}

/************************ (C) COPYRIGHT STMicroelectronics *****END OF FILE****/
